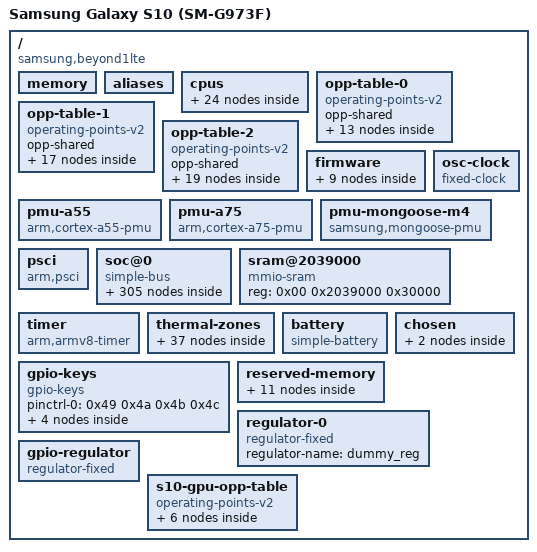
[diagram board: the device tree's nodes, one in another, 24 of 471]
// SPDX-License-Identifier: GPL-2.0-only
/* Flattened working source derived from chiffathefox/u-boot at
 * dec4927b4ad5b789b0854050096fc80250627de7.
 * Original Exynos device-tree source notices:
 * Copyright (c) 2025 chiffathefox <chiffathefoxx@gmail.com>
 * Copyright (c) 2026 chiffathefox <chiffathefoxx@gmail.com>
 * GPL version 2 is selected from the upstream GPL-2.0 OR BSD-3-Clause grant;
 * the included TMU source is GPL-2.0. Local port changes use the project GPLv2 grant.
 * Source/capture comparison and scope: docs/public/PROVENANCE.md.
 */
/dts-v1/;

/ {
	compatible = "samsung,beyond1lte", "samsung,exynos9820";
	#address-cells = <0x02>;
	#size-cells = <0x01>;
	interrupt-parent = <0x01>;
	model = "Samsung Galaxy S10 (SM-G973F)";
	chassis-type = "handset";

	memory {
		reg = <0x00 0x80000000 0x3ab00000 0x00 0xc0000000 0x20000000 0x00 0xe1900000 0x1e700000 0x08 0x80000000 0x80000000 0x09 0x00 0x80000000 0x09 0x80000000 0x80000000>;
		device_type = "memory";
	};

	aliases {
		pinctrl0 = "/soc@0/pinctrl@15850000";
		pinctrl1 = "/soc@0/pinctrl@18c60000";
		pinctrl2 = "/soc@0/pinctrl@15c30000";
		pinctrl3 = "/soc@0/pinctrl@13030000";
		pinctrl4 = "/soc@0/pinctrl@13c40000";
		pinctrl5 = "/soc@0/pinctrl@10430000";
		pinctrl6 = "/soc@0/pinctrl@10830000";
		pinctrl7 = "/soc@0/pinctrl@15580000";
		serial1 = "/soc@0/serial@10840000";
	};

	cpus {
		#address-cells = <0x01>;
		#size-cells = <0x00>;

		cpu-map {

			cluster0 {

				core0 {
					cpu = <0x02>;
				};

				core1 {
					cpu = <0x03>;
				};

				core2 {
					cpu = <0x04>;
				};

				core3 {
					cpu = <0x05>;
				};
			};

			cluster1 {

				core0 {
					cpu = <0x06>;
				};

				core1 {
					cpu = <0x07>;
				};
			};

			cluster2 {

				core0 {
					cpu = <0x08>;
				};

				core1 {
					cpu = <0x09>;
				};
			};
		};

		cpu@0 {
			device_type = "cpu";
			compatible = "arm,cortex-a55";
			reg = <0x00>;
			clocks = <0x0a 0x02>;
			#cooling-cells = <0x02>;
			enable-method = "psci";
			cpu-idle-states = <0x0b>;
			capacity-dmips-mhz = <0x110>;
			dynamic-power-coefficient = <0xa0>;
			operating-points-v2 = <0x0c>;
			phandle = <0x02>;
		};

		cpu@1 {
			device_type = "cpu";
			compatible = "arm,cortex-a55";
			reg = <0x01>;
			clocks = <0x0a 0x02>;
			#cooling-cells = <0x02>;
			enable-method = "psci";
			cpu-idle-states = <0x0b>;
			capacity-dmips-mhz = <0x110>;
			dynamic-power-coefficient = <0xa0>;
			operating-points-v2 = <0x0c>;
			phandle = <0x03>;
		};

		cpu@2 {
			device_type = "cpu";
			compatible = "arm,cortex-a55";
			reg = <0x02>;
			clocks = <0x0a 0x02>;
			#cooling-cells = <0x02>;
			enable-method = "psci";
			cpu-idle-states = <0x0b>;
			capacity-dmips-mhz = <0x110>;
			dynamic-power-coefficient = <0xa0>;
			operating-points-v2 = <0x0c>;
			phandle = <0x04>;
		};

		cpu@3 {
			device_type = "cpu";
			compatible = "arm,cortex-a55";
			reg = <0x03>;
			clocks = <0x0a 0x02>;
			#cooling-cells = <0x02>;
			enable-method = "psci";
			cpu-idle-states = <0x0b>;
			capacity-dmips-mhz = <0x110>;
			dynamic-power-coefficient = <0xa0>;
			operating-points-v2 = <0x0c>;
			phandle = <0x05>;
		};

		cpu@4 {
			device_type = "cpu";
			compatible = "arm,cortex-a75";
			reg = <0x04>;
			clocks = <0x0a 0x03>;
			#cooling-cells = <0x02>;
			enable-method = "psci";
			cpu-idle-states = <0x0d>;
			capacity-dmips-mhz = <0x213>;
			dynamic-power-coefficient = <0x140>;
			operating-points-v2 = <0x0e>;
			phandle = <0x06>;
		};

		cpu@5 {
			device_type = "cpu";
			compatible = "arm,cortex-a75";
			reg = <0x05>;
			clocks = <0x0a 0x03>;
			#cooling-cells = <0x02>;
			enable-method = "psci";
			cpu-idle-states = <0x0d>;
			capacity-dmips-mhz = <0x213>;
			dynamic-power-coefficient = <0x140>;
			operating-points-v2 = <0x0e>;
			phandle = <0x07>;
		};

		cpu@100 {
			device_type = "cpu";
			compatible = "samsung,mongoose-m4";
			reg = <0x100>;
			clocks = <0x0a 0x04>;
			#cooling-cells = <0x02>;
			enable-method = "psci";
			cpu-idle-states = <0x0f>;
			capacity-dmips-mhz = <0x311>;
			dynamic-power-coefficient = <0x2f8>;
			operating-points-v2 = <0x10>;
			phandle = <0x08>;
		};

		cpu@101 {
			device_type = "cpu";
			compatible = "samsung,mongoose-m4";
			reg = <0x101>;
			clocks = <0x0a 0x04>;
			#cooling-cells = <0x02>;
			enable-method = "psci";
			cpu-idle-states = <0x0f>;
			capacity-dmips-mhz = <0x311>;
			dynamic-power-coefficient = <0x2f8>;
			operating-points-v2 = <0x10>;
			phandle = <0x09>;
		};

		idle-states {
			entry-method = "psci";

			cpu-ananke-sleep {
				samsung,cpuidle-disabled-by-default = "deferred-until-userspace-v1";
				idle-state-name = "c2";
				compatible = "arm,idle-state";
				arm,psci-suspend-param = <0x10000>;
				entry-latency-us = <0x46>;
				exit-latency-us = <0xa0>;
				min-residency-us = <0x7d0>;
				status = "okay";
				phandle = <0x0b>;
			};

			cpu-prometheus-sleep {
				samsung,cpuidle-disabled-by-default = "deferred-until-userspace-v1";
				idle-state-name = "c2";
				compatible = "arm,idle-state";
				arm,psci-suspend-param = <0x10000>;
				entry-latency-us = <0x96>;
				exit-latency-us = <0xbe>;
				min-residency-us = <0x9c4>;
				status = "okay";
				phandle = <0x0d>;
			};

			cpu-cheetah-sleep {
				samsung,cpuidle-disabled-by-default = "deferred-until-userspace-v1";
				idle-state-name = "c2";
				compatible = "arm,idle-state";
				arm,psci-suspend-param = <0x10000>;
				entry-latency-us = <0xeb>;
				exit-latency-us = <0xdc>;
				min-residency-us = <0xdac>;
				status = "okay";
				phandle = <0x0f>;
			};
		};
	};

	opp-table-0 {
		compatible = "operating-points-v2";
		opp-shared;
		phandle = <0x0c>;

		opp-442000000 {
			opp-hz = <0x00 0x1a586280>;
			opp-microvolt = <0x8de82>;
			clock-latency-ns = <0x7a120>;
		};

		opp-546000000 {
			opp-hz = <0x00 0x208b4c80>;
			opp-microvolt = <0x95894>;
			clock-latency-ns = <0x7a120>;
		};

		opp-650000000 {
			opp-hz = <0x00 0x26be3680>;
			opp-microvolt = <0x9a1d2>;
			clock-latency-ns = <0x7a120>;
		};

		opp-806000000 {
			opp-hz = <0x00 0x300a9580>;
			opp-microvolt = <0xa4cb8>;
			clock-latency-ns = <0x7a120>;
		};

		opp-949000000 {
			opp-hz = <0x00 0x38909740>;
			opp-microvolt = <0xadf34>;
			clock-latency-ns = <0x7a120>;
		};

		opp-1053000000 {
			opp-hz = <0x00 0x3ec38140>;
			opp-microvolt = <0xb5946>;
			clock-latency-ns = <0x7a120>;
		};

		opp-1157000000 {
			opp-hz = <0x00 0x44f66b40>;
			opp-microvolt = <0xbd358>;
			clock-latency-ns = <0x7a120>;
		};

		opp-1300000000 {
			opp-hz = <0x00 0x4d7c6d00>;
			opp-microvolt = <0xc7e3e>;
			clock-latency-ns = <0x7a120>;
		};

		opp-1456000000 {
			opp-hz = <0x00 0x56c8cc00>;
			opp-microvolt = <0xd418e>;
			clock-latency-ns = <0x7a120>;
		};

		opp-1586000000 {
			opp-hz = <0x00 0x5e887080>;
			opp-microvolt = <0xe04de>;
			clock-latency-ns = <0x7a120>;
		};

		opp-1742000000 {
			opp-hz = <0x00 0x67d4cf80>;
			opp-microvolt = <0xf4240>;
			clock-latency-ns = <0x7a120>;
		};

		opp-1846000000 {
			opp-hz = <0x00 0x6e07b980>;
			opp-microvolt = <0x100590>;
			clock-latency-ns = <0x7a120>;
		};

		opp-1950000000 {
			opp-hz = <0x00 0x743aa380>;
			opp-microvolt = <0x10b076>;
			clock-latency-ns = <0x7a120>;
		};
	};

	opp-table-1 {
		compatible = "operating-points-v2";
		opp-shared;
		phandle = <0x0e>;

		opp-507000000 {
			opp-hz = <0x00 0x1e3834c0>;
			opp-microvolt = <0x8f6ec>;
			clock-latency-ns = <0x7a120>;
		};

		opp-650000000 {
			opp-hz = <0x00 0x26be3680>;
			opp-microvolt = <0x9402a>;
			clock-latency-ns = <0x7a120>;
		};

		opp-754000000 {
			opp-hz = <0x00 0x2cf12080>;
			opp-microvolt = <0x9a1d2>;
			clock-latency-ns = <0x7a120>;
		};

		opp-845000000 {
			opp-hz = <0x00 0x325dad40>;
			opp-microvolt = <0x9eb10>;
			clock-latency-ns = <0x7a120>;
		};

		opp-962000000 {
			opp-hz = <0x00 0x3956f480>;
			opp-microvolt = <0xa1be4>;
			clock-latency-ns = <0x7a120>;
		};

		opp-1066000000 {
			opp-hz = <0x00 0x3f89de80>;
			opp-microvolt = <0xa6522>;
			clock-latency-ns = <0x7a120>;
		};

		opp-1222000000 {
			opp-hz = <0x00 0x48d63d80>;
			opp-microvolt = <0xb1008>;
			clock-latency-ns = <0x7a120>;
		};

		opp-1404000000 {
			opp-hz = <0x00 0x53af5700>;
			opp-microvolt = <0xb8a1a>;
			clock-latency-ns = <0x7a120>;
		};

		opp-1508000000 {
			opp-hz = <0x00 0x59e24100>;
			opp-microvolt = <0xbebc2>;
			clock-latency-ns = <0x7a120>;
		};

		opp-1586000000 {
			opp-hz = <0x00 0x5e887080>;
			opp-microvolt = <0xc1c96>;
			clock-latency-ns = <0x7a120>;
		};

		opp-1690000000 {
			opp-hz = <0x00 0x64bb5a80>;
			opp-microvolt = <0xc7e3e>;
			clock-latency-ns = <0x7a120>;
		};

		opp-1794000000 {
			opp-hz = <0x00 0x6aee4480>;
			opp-microvolt = <0xcf850>;
			clock-latency-ns = <0x7a120>;
		};

		opp-1898000000 {
			opp-hz = <0x00 0x71212e80>;
			opp-microvolt = <0xda336>;
			clock-latency-ns = <0x7a120>;
		};

		opp-2002000000 {
			opp-hz = <0x00 0x77541880>;
			opp-microvolt = <0xe04de>;
			clock-latency-ns = <0x7a120>;
		};

		opp-2106000000 {
			opp-hz = <0x00 0x7d870280>;
			opp-microvolt = <0xe975a>;
			clock-latency-ns = <0x7a120>;
		};

		opp-2210000000 {
			opp-hz = <0x00 0x83b9ec80>;
			opp-microvolt = <0xf5aaa>;
			clock-latency-ns = <0x7a120>;
		};

		opp-2314000000 {
			opp-hz = <0x00 0x89ecd680>;
			opp-microvolt = <0x101dfa>;
			clock-latency-ns = <0x7a120>;
		};
	};

	opp-table-2 {
		compatible = "operating-points-v2";
		opp-shared;
		phandle = <0x10>;

		opp-520000000 {
			opp-hz = <0x00 0x1efe9200>;
			opp-microvolt = <0x8f6ec>;
			clock-latency-ns = <0x7a120>;
		};

		opp-624000000 {
			opp-hz = <0x00 0x25317c00>;
			opp-microvolt = <0x927c0>;
			clock-latency-ns = <0x7a120>;
		};

		opp-728000000 {
			opp-hz = <0x00 0x2b646600>;
			opp-microvolt = <0x9402a>;
			clock-latency-ns = <0x7a120>;
		};

		opp-819000000 {
			opp-hz = <0x00 0x30d0f2c0>;
			opp-microvolt = <0x970fe>;
			clock-latency-ns = <0x7a120>;
		};

		opp-936000000 {
			opp-hz = <0x00 0x37ca3a00>;
			opp-microvolt = <0x9ba3c>;
			clock-latency-ns = <0x7a120>;
		};

		opp-1040000000 {
			opp-hz = <0x00 0x3dfd2400>;
			opp-microvolt = <0x9d2a6>;
			clock-latency-ns = <0x7a120>;
		};

		opp-1144000000 {
			opp-hz = <0x00 0x44300e00>;
			opp-microvolt = <0xa4cb8>;
			clock-latency-ns = <0x7a120>;
		};

		opp-1248000000 {
			opp-hz = <0x00 0x4a62f800>;
			opp-microvolt = <0xa7d8c>;
			clock-latency-ns = <0x7a120>;
		};

		opp-1378000000 {
			opp-hz = <0x00 0x52229c80>;
			opp-microvolt = <0xac6ca>;
			clock-latency-ns = <0x7a120>;
		};

		opp-1456000000 {
			opp-hz = <0x00 0x56c8cc00>;
			opp-microvolt = <0xaf79e>;
			clock-latency-ns = <0x7a120>;
		};

		opp-1560000000 {
			opp-hz = <0x00 0x5cfbb600>;
			opp-microvolt = <0xb5946>;
			clock-latency-ns = <0x7a120>;
		};

		opp-1664000000 {
			opp-hz = <0x00 0x632ea000>;
			opp-microvolt = <0xbbaee>;
			clock-latency-ns = <0x7a120>;
		};

		opp-1820000000 {
			opp-hz = <0x00 0x6c7aff00>;
			opp-microvolt = <0xc1c96>;
			clock-latency-ns = <0x7a120>;
		};

		opp-1976000000 {
			opp-hz = <0x00 0x75c75e00>;
			opp-microvolt = <0xcc77c>;
			clock-latency-ns = <0x7a120>;
		};

		opp-2080000000 {
			opp-hz = <0x00 0x7bfa4800>;
			opp-microvolt = <0xd418e>;
			clock-latency-ns = <0x7a120>;
		};

		opp-2236000000 {
			opp-hz = <0x00 0x8546a700>;
			opp-microvolt = <0xdd40a>;
			clock-latency-ns = <0x7a120>;
		};

		opp-2340000000 {
			opp-hz = <0x00 0x8b799100>;
			opp-microvolt = <0xe35b2>;
			clock-latency-ns = <0x7a120>;
		};

		opp-2470000000 {
			opp-hz = <0x00 0x93393580>;
			opp-microvolt = <0xf116c>;
			clock-latency-ns = <0x7a120>;
		};

		opp-2530000000 {
			opp-hz = <0x00 0x96ccbc80>;
			opp-microvolt = <0xf8b7e>;
			clock-latency-ns = <0x7a120>;
		};
	};

	firmware {

		power-management {
			compatible = "samsung,exynos9820-acpm-ipc";
			#clock-cells = <0x01>;
			assigned-clocks = <0x0a 0x00 0x0a 0x01 0x0a 0x02 0x0a 0x03 0x0a 0x04 0x0a 0x05 0x0a 0x06 0x0a 0x07 0x0a 0x08 0x0a 0x09 0x0a 0x0a 0x0a 0x0b 0x0a 0x0c 0x0a 0x0d 0x0a 0x0e>;
			assigned-clock-rates = <0x7cc0a540 0x1fd43180 0x3ec38140 0x48d63d80 0x52229c80 0x9f437c0 0x1fd43180 0x17d7840 0x119557c0 0x3f89de80 0x94c5f00 0x258d0980 0x26be3680 0x3567e00 0x7fcad80>;
			mboxes = <0x11>;
			shmem = <0x12>;
			phandle = <0x0a>;

			pmic-1 {
				compatible = "samsung,s2mps19-pmic";
				interrupts-extended = <0x13 0x01 0x08>;
				wakeup-source;

				regulators {

					ldo19m {
						regulator-name = "tsp_io";
						regulator-min-microvolt = <0x1b7740>;
						regulator-max-microvolt = <0x1b7740>;
						regulator-boot-on;
						phandle = <0x1c>;
					};

					ldo27m {
						regulator-name = "tsp_avdd";
						regulator-min-microvolt = <0x2dc6c0>;
						regulator-max-microvolt = <0x2dc6c0>;
						regulator-boot-on;
						phandle = <0x1b>;
					};

					ldo17m {
						regulator-name = "vdd_pmic_codec_1p8";
						regulator-min-microvolt = <0x1b7740>;
						regulator-max-microvolt = <0x1b7740>;
						regulator-always-on;
						regulator-boot-on;
						phandle = <0x58>;
					};

					ldo18m {
						regulator-name = "vdd_codec_1p2";
						regulator-min-microvolt = <0x124f80>;
						regulator-max-microvolt = <0x124f80>;
						phandle = <0x59>;
					};

					ldo22m {
						regulator-name = "VDD_NFC_1P8";
						regulator-min-microvolt = <0x1b7740>;
						regulator-max-microvolt = <0x1b7740>;
						regulator-boot-on;
						regulator-always-on;
					};

					ldo21m {
						regulator-name = "vdd_mcu_1p8";
						regulator-min-microvolt = <0x1b7740>;
						regulator-max-microvolt = <0x1b7740>;
						regulator-boot-on;
						regulator-always-on;
					};
				};
			};
		};
	};

	osc-clock {
		compatible = "fixed-clock";
		#clock-cells = <0x00>;
		clock-output-names = "oscclk";
		clock-frequency = <0x18cba80>;
		phandle = <0x14>;
	};

	pmu-a55 {
		compatible = "arm,cortex-a55-pmu";
		interrupts = <0x00 0x8d 0x04 0x00 0x8e 0x04 0x00 0x8f 0x04 0x00 0x90 0x04>;
		interrupt-affinity = <0x02 0x03 0x04 0x05>;
	};

	pmu-a75 {
		compatible = "arm,cortex-a75-pmu";
		interrupts = <0x00 0x91 0x04 0x00 0x92 0x04>;
		interrupt-affinity = <0x06 0x07>;
	};

	pmu-mongoose-m4 {
		compatible = "samsung,mongoose-pmu";
		interrupts = <0x00 0xae 0x04 0x00 0xaf 0x04>;
		interrupt-affinity = <0x08 0x09>;
	};

	psci {
		compatible = "arm,psci";
		method = "smc";
		cpu_suspend = <0xc4000001>;
		cpu_off = <0x84000002>;
		cpu_on = <0xc4000003>;
	};

	soc@0 {
		compatible = "simple-bus";
		#address-cells = <0x01>;
		#size-cells = <0x01>;
		ranges = <0x00 0x00 0x00 0x20000000>;

		watchdog@10050000 {
			status = "okay";
			timeout-sec = <0x14>;
			samsung,syscon-phandle = <0x21>;
			clock-names = "watchdog", "watchdog_src";
			clocks = <0x17 0x16 0x14>;
			interrupts = <0x00 0x1d0 0x04>;
			reg = <0x10050000 0x100>;
			compatible = "samsung,exynos9820-wdt";
		};

		sysmmu@190a0000 {
			phandle = <0xaa>;
			#iommu-cells = <0x00>;
			clocks = <0x39 0x3c>;
			clock-names = "sysmmu";
			interrupts = <0x00 0xd4 0x04>;
			reg = <0x190a0000 0x9000>;
			compatible = "samsung,exynos-sysmmu";
		};

		display-controller@19030000 {
			interrupt-names = "frame-done", "frame-start";
			phandle = <0xab>;
			iommus = <0xaa>;
			height-mm = <0x8c>;
			width-mm = <0x42>;
			interrupts = <0x00 0xb8 0x04 0x00 0xb7 0x04>;
			memory-region = <0xa9>;
			reg-names = "decon", "dma", "dsim";
			reg = <0x19030000 0x10000 0x19071000 0x1000 0x19080000 0x300>;
			compatible = "samsung,exynos9820-decon-takeover";
		};

		flexpmu-dbg@204bc00 {
			compatible = "samsung,exynos9820-flexpmu-dbg";
			reg = <0x204bc00 0x400 0x15950000 0x100>;
			reg-names = "data", "rtc";
		};

		clock-controller@10020000 {
			compatible = "samsung,exynos9820-cmu-peris";
			reg = <0x10020000 0x10000>;
			#clock-cells = <0x01>;
			clock-names = "oscclk", "bus";
			clocks = <0x14 0x15 0x6b>;
			samsung,sysreg = <0x16>;
			phandle = <0x17>;
		};

		syscon@10030000 {
			compatible = "samsung,exynos9820-peris-sysreg", "syscon";
			reg = <0x10030000 0x10000>;
			clocks = <0x17 0x13>;
			phandle = <0x16>;
		};

		timer@10040000 {
			samsung,prefer-local-timers;
			compatible = "samsung,exynos4210-mct";
			reg = <0x10040000 0x800>;
			clocks = <0x14 0x17 0x0d>;
			clock-names = "fin_pll", "mct";
			interrupts = <0x00 0x1d2 0x04 0x00 0x1d3 0x04 0x00 0x1d4 0x04 0x00 0x1d5 0x04 0x00 0x1d6 0x04 0x00 0x1d7 0x04 0x00 0x1d8 0x04 0x00 0x1d9 0x04 0x00 0x1da 0x04 0x00 0x1db 0x04 0x00 0x1dc 0x04 0x00 0x1dd 0x04>;
		};

		thermal-sensor@10090000 {
			compatible = "samsung,exynos9820-tmu-top";
			reg = <0x10090000 0x800>;
			clocks = <0x17 0x15 0x17 0x14>;
			interrupts = <0x00 0x1de 0x04>;
			samsung,acpm-ipc = <0x0a>;
			#thermal-sensor-cells = <0x01>;
			phandle = <0x43>;
		};

		interrupt-controller@10100000 {
			compatible = "arm,cortex-a15-gic", "arm,cortex-a9-gic";
			#interrupt-cells = <0x03>;
			#address-cells = <0x00>;
			interrupt-controller;
			reg = <0x10101000 0x1000 0x10102000 0x1000 0x10104000 0x2000 0x10106000 0x2000>;
			interrupts = <0x01 0x09 0xf04>;
			phandle = <0x01>;
		};

		clock-controller@10400000 {
			compatible = "samsung,exynos9820-cmu-peric0";
			reg = <0x10400000 0x10000>;
			#clock-cells = <0x01>;
			clock-names = "oscclk", "bus", "ip";
			clocks = <0x14 0x15 0x67 0x15 0x68>;
			samsung,sysreg = <0x18>;
			phandle = <0x19>;
		};

		syscon@10420000 {
			compatible = "samsung,exynos9820-peric0-sysreg", "syscon";
			reg = <0x10420000 0x10000>;
			clocks = <0x19 0x2f>;
			phandle = <0x18>;
		};

		pinctrl@10430000 {
			compatible = "samsung,exynos9820-pinctrl";
			reg = <0x10430000 0x1000>;
			clocks = <0x19 0x1f>;
			clock-names = "pclk";
			interrupts = <0x00 0x17c 0x04>;

			gpp0-gpio-bank {
				gpio-controller;
				#gpio-cells = <0x02>;
				interrupt-controller;
				#interrupt-cells = <0x02>;
				phandle = <0x53>;
			};

			gpp1-gpio-bank {
				gpio-controller;
				#gpio-cells = <0x02>;
				interrupt-controller;
				#interrupt-cells = <0x02>;
			};

			gpp2-gpio-bank {
				gpio-controller;
				#gpio-cells = <0x02>;
				interrupt-controller;
				#interrupt-cells = <0x02>;
			};

			gpp3-gpio-bank {
				gpio-controller;
				#gpio-cells = <0x02>;
				interrupt-controller;
				#interrupt-cells = <0x02>;
			};

			gpg0-gpio-bank {
				gpio-controller;
				#gpio-cells = <0x02>;
				interrupt-controller;
				#interrupt-cells = <0x02>;
				phandle = <0x51>;
			};

			gpg1-gpio-bank {
				gpio-controller;
				#gpio-cells = <0x02>;
				interrupt-controller;
				#interrupt-cells = <0x02>;
				phandle = <0x4e>;
			};

			gpg2-gpio-bank {
				gpio-controller;
				#gpio-cells = <0x02>;
				interrupt-controller;
				#interrupt-cells = <0x02>;
				phandle = <0x86>;
			};

			gpg4-gpio-bank {
				gpio-controller;
				#gpio-cells = <0x02>;
				interrupt-controller;
				#interrupt-cells = <0x02>;
				phandle = <0x75>;
			};

			hsi2c10-bus-pins {
				samsung,pins = "gpp1-4", "gpp1-5";
				samsung,pin-function = <0x02>;
				samsung,pin-pud = <0x00>;
				samsung,pin-drv = <0x00>;
				phandle = <0x1a>;
			};

			s10-spi2-bus {
				samsung,pins = "gpp0-4", "gpp0-5", "gpp0-6";
				samsung,pin-function = <0x02>;
				samsung,pin-pud = <0x00>;
				phandle = <0x54>;
			};

			s10-spi2-cs {
				samsung,pins = "gpp0-7";
				samsung,pin-function = <0x01>;
				samsung,pin-pud = <0x03>;
				phandle = <0x55>;
			};

			s10-codec-reset {
				samsung,pins = "gpg1-0";
				samsung,pin-function = <0x01>;
				samsung,pin-pud = <0x00>;
				phandle = <0x56>;
			};

			s10-bt-btwake {
				samsung,pins = "gpg2-0";
				samsung,pin-function = <0x01>;
				samsung,pin-pud = <0x00>;
				phandle = <0x99>;
			};

			s10-shub-pwr {
				samsung,pins = "gpg0-2";
				samsung,pin-function = <0x01>;
				samsung,pin-pud = <0x01>;
				samsung,pin-drv = <0x03>;
				phandle = <0xa3>;
			};

			s10-shub-mcu-req {
				samsung,pins = "gpg4-1";
				samsung,pin-function = <0x01>;
				samsung,pin-pud = <0x00>;
				samsung,pin-drv = <0x03>;
				phandle = <0xa4>;
			};

			s10-shub-mcu-resp {
				samsung,pins = "gpg4-2";
				samsung,pin-function = <0x00>;
				samsung,pin-pud = <0x00>;
				samsung,pin-drv = <0x03>;
				phandle = <0xa5>;
			};
		};

		serial@10440000 {
			compatible = "samsung,exynos7870-uart", "samsung,exynos8895-uart";
			reg = <0x10440000 0x100>;
			interrupts = <0x00 0x17d 0x04>;
			clock-names = "uart", "clk_uart_baud0";
			clocks = <0x19 0x31 0x19 0x30>;
			samsung,uart-fifosize = <0x100>;
			status = "okay";
		};

		usi@104b00c0 {
			compatible = "samsung,exynos850-usi";
			reg = <0x104b00c0 0x20>;
			ranges;
			clock-names = "pclk", "ipclk";
			clocks = <0x19 0x41 0x19 0x40>;
			#address-cells = <0x01>;
			#size-cells = <0x01>;
			samsung,sysreg = <0x18 0x101c>;
			status = "okay";
			samsung,mode = <0x03>;

			i2c@104b0000 {
				compatible = "samsung,exynosautov9-hsi2c";
				reg = <0x104b0000 0xc0>;
				clock-names = "hsi2c", "hsi2c_pclk";
				clocks = <0x19 0x40 0x19 0x41>;
				interrupts = <0x00 0x184 0x04>;
				pinctrl-0 = <0x1a>;
				pinctrl-names = "default";
				#address-cells = <0x01>;
				#size-cells = <0x00>;
				status = "okay";
				clock-frequency = <0x61a80>;

				touchscreen@48 {
					compatible = "samsung,s6sy761";
					reg = <0x48>;
					avdd-supply = <0x1b>;
					vdd-supply = <0x1c>;
					interrupts-extended = <0x1d 0x00 0x08>;
					pinctrl-0 = <0x1e>;
					pinctrl-names = "default";
				};
			};
		};

		pwm@10510000 {
			compatible = "samsung,exynos4210-pwm";
			reg = <0x10510000 0x1000>;
			samsung,pwm-outputs = <0x00 0x01 0x02 0x03 0x04>;
			#pwm-cells = <0x03>;
			clocks = <0x14>;
			clock-names = "timers";
			status = "okay";
			phandle = <0x35>;
		};

		clock-controller@10800000 {
			compatible = "samsung,exynos9820-cmu-peric1";
			reg = <0x10800000 0x10000>;
			#clock-cells = <0x01>;
			clock-names = "oscclk", "bus";
			clocks = <0x14 0x15 0x69>;
			samsung,sysreg = <0x1f>;
			phandle = <0x5a>;
		};

		syscon@10820000 {
			compatible = "samsung,exynos9820-peric1-sysreg", "syscon";
			reg = <0x10820000 0x10000>;
			phandle = <0x1f>;
		};

		pinctrl@10830000 {
			compatible = "samsung,exynos9820-pinctrl";
			reg = <0x10830000 0x1000>;
			interrupts = <0x00 0x197 0x04>;

			gpp4-gpio-bank {
				gpio-controller;
				#gpio-cells = <0x02>;
				interrupt-controller;
				#interrupt-cells = <0x02>;
			};

			gpp5-gpio-bank {
				gpio-controller;
				#gpio-cells = <0x02>;
				interrupt-controller;
				#interrupt-cells = <0x02>;
			};

			gpp6-gpio-bank {
				gpio-controller;
				#gpio-cells = <0x02>;
				interrupt-controller;
				#interrupt-cells = <0x02>;
				phandle = <0x9c>;
			};

			gpc0-gpio-bank {
				gpio-controller;
				#gpio-cells = <0x02>;
				interrupt-controller;
				#interrupt-cells = <0x02>;
			};

			gpc1-gpio-bank {
				gpio-controller;
				#gpio-cells = <0x02>;
				interrupt-controller;
				#interrupt-cells = <0x02>;
			};

			gpd0-gpio-bank {
				gpio-controller;
				#gpio-cells = <0x02>;
				interrupt-controller;
				#interrupt-cells = <0x02>;
			};

			gpg3-gpio-bank {
				gpio-controller;
				#gpio-cells = <0x02>;
				interrupt-controller;
				#interrupt-cells = <0x02>;
				phandle = <0x7a>;
			};

			gph0-gpio-bank {
				gpio-controller;
				#gpio-cells = <0x02>;
				interrupt-controller;
				#interrupt-cells = <0x02>;
				phandle = <0xa2>;
			};

			gph1-gpio-bank {
				gpio-controller;
				#gpio-cells = <0x02>;
				interrupt-controller;
				#interrupt-cells = <0x02>;
				phandle = <0x5f>;
			};

			s10-amp-i2c-bus {
				samsung,pins = "gph0-6", "gph0-7";
				samsung,pin-function = <0x03>;
				samsung,pin-pud = <0x00>;
				phandle = <0x5b>;
			};

			s10-amp-reset-released {
				samsung,pins = "gph1-1", "gph1-2";
				samsung,pin-function = <0x01>;
				samsung,pin-pud = <0x00>;
				samsung,pin-val = <0x01>;
			};

			s10-amp-reset {
				samsung,pins = "gph1-1", "gph1-2";
				samsung,pin-function = <0x01>;
				samsung,pin-pud = <0x00>;
				phandle = <0x5c>;
			};

			s10-camera-pmic-bus {
				samsung,pins = "gpp6-0", "gpp6-1";
				samsung,pin-function = <0x02>;
				samsung,pin-pud = <0x00>;
				samsung,pin-drv = <0x00>;
				phandle = <0x66>;
			};

			s10-uw-i2c-idle {
				samsung,pins = "gpc0-2", "gpc0-3";
				samsung,pin-function = <0x00>;
				samsung,pin-pud = <0x00>;
				phandle = <0x67>;
			};

			s10-uw-i2c-active {
				samsung,pins = "gpc0-2", "gpc0-3";
				samsung,pin-function = <0x02>;
				samsung,pin-pud = <0x00>;
				samsung,pin-drv = <0x00>;
				phandle = <0x69>;
			};

			s10-uw-mclk-idle {
				samsung,pins = "gpc1-7";
				samsung,pin-function = <0x01>;
				samsung,pin-val = <0x00>;
				samsung,pin-pud = <0x01>;
				phandle = <0x68>;
			};

			s10-uw-mclk-active {
				samsung,pins = "gpc1-7";
				samsung,pin-function = <0x02>;
				samsung,pin-pud = <0x00>;
				samsung,pin-drv = <0x00>;
				phandle = <0x6a>;
			};

			s10-tele-i2c-idle {
				samsung,pins = "gpp4-6", "gpp4-7";
				samsung,pin-function = <0x00>;
				samsung,pin-pud = <0x00>;
				phandle = <0x76>;
			};

			s10-tele-i2c-active {
				samsung,pins = "gpp4-6", "gpp4-7";
				samsung,pin-function = <0x03>;
				samsung,pin-pud = <0x00>;
				samsung,pin-drv = <0x00>;
				phandle = <0x78>;
			};

			s10-front-i2c-idle {
				samsung,pins = "gpc0-4", "gpc0-5";
				samsung,pin-function = <0x00>;
				samsung,pin-pud = <0x00>;
				phandle = <0x82>;
			};

			s10-front-i2c-active {
				samsung,pins = "gpc0-4", "gpc0-5";
				samsung,pin-function = <0x02>;
				samsung,pin-pud = <0x00>;
				samsung,pin-drv = <0x00>;
				phandle = <0x84>;
			};

			s10-af-i2c-idle {
				samsung,pins = "gpc0-6", "gpc0-7";
				samsung,pin-function = <0x00>;
				samsung,pin-pud = <0x00>;
				phandle = <0x8b>;
			};

			s10-af-i2c-active {
				samsung,pins = "gpc0-6", "gpc0-7";
				samsung,pin-function = <0x02>;
				samsung,pin-pud = <0x02>;
				samsung,pin-drv = <0x00>;
				phandle = <0x8c>;
			};

			s10-mclk0-idle {
				samsung,pins = "gpc1-4";
				samsung,pin-function = <0x01>;
				samsung,pin-val = <0x00>;
				samsung,pin-pud = <0x01>;
				phandle = <0x77>;
			};

			s10-mclk0-active {
				samsung,pins = "gpc1-4";
				samsung,pin-function = <0x02>;
				samsung,pin-pud = <0x00>;
				samsung,pin-drv = <0x00>;
				phandle = <0x79>;
			};

			s10-mclk1-idle {
				samsung,pins = "gpc1-5";
				samsung,pin-function = <0x01>;
				samsung,pin-val = <0x00>;
				samsung,pin-pud = <0x01>;
				phandle = <0x83>;
			};

			s10-mclk1-active {
				samsung,pins = "gpc1-5";
				samsung,pin-function = <0x02>;
				samsung,pin-pud = <0x00>;
				samsung,pin-drv = <0x00>;
				phandle = <0x85>;
			};

			s10-front-af-i2c-idle {
				samsung,pins = "gpp5-2", "gpp5-3";
				samsung,pin-function = <0x00>;
				samsung,pin-pud = <0x00>;
				phandle = <0x93>;
			};

			s10-front-af-i2c-active {
				samsung,pins = "gpp5-2", "gpp5-3";
				samsung,pin-function = <0x03>;
				samsung,pin-pud = <0x00>;
				samsung,pin-drv = <0x00>;
				phandle = <0x94>;
			};

			s10-nfc-i2c {
				samsung,pins = "gpp5-0", "gpp5-1";
				samsung,pin-function = <0x02>;
				samsung,pin-pud = <0x00>;
				samsung,pin-drv = <0x00>;
				phandle = <0x9b>;
			};

			s10-nfc-en {
				samsung,pins = "gpp6-2";
				samsung,pin-function = <0x01>;
				samsung,pin-pud = <0x00>;
				phandle = <0x9d>;
			};

			s10-nfc-firm {
				samsung,pins = "gpp6-3";
				samsung,pin-function = <0x01>;
				samsung,pin-pud = <0x00>;
				phandle = <0x9e>;
			};

			s10-shub-spi {
				samsung,pins = "gph0-2", "gph0-1", "gph0-0";
				samsung,pin-function = <0x02>;
				samsung,pin-pud = <0x00>;
				samsung,pin-drv = <0x00>;
				phandle = <0xa0>;
			};

			s10-shub-cs {
				samsung,pins = "gph0-3";
				samsung,pin-function = <0x01>;
				samsung,pin-pud = <0x00>;
				samsung,pin-drv = <0x00>;
				phandle = <0xa1>;
			};

			s10-main-i2c-idle {
				samsung,pins = "gpc0-0", "gpc0-1";
				samsung,pin-function = <0x00>;
				samsung,pin-pud = <0x00>;
				phandle = <0xac>;
			};

			s10-main-i2c-active {
				samsung,pins = "gpc0-0", "gpc0-1";
				samsung,pin-function = <0x02>;
				samsung,pin-pud = <0x00>;
				samsung,pin-drv = <0x00>;
				phandle = <0xad>;
			};
		};

		clock-controller@10a00000 {
			compatible = "samsung,exynos9820-cmu-fsys0a";
			reg = <0x10a00000 0x10000>;
			#clock-cells = <0x01>;
			clock-names = "oscclk", "usb31drd", "usbdp_debug";
			clocks = <0x14 0x15 0x53 0x15 0x7a>;
			phandle = <0x20>;
		};

		phy@10b00000 {
			compatible = "samsung,exynos990-usbdrd-phy";
			reg = <0x10b00000 0x200>;
			#phy-cells = <0x01>;
			clock-names = "phy", "ref";
			clocks = <0x20 0x0a 0x14>;
			samsung,pmu-syscon = <0x21>;
			status = "okay";
			phandle = <0x23>;
		};

		usb@10c00000 {
			compatible = "samsung,exynos850-dwusb3";
			ranges = <0x00 0x10c00000 0x10000>;
			clock-names = "bus_early", "ref";
			clocks = <0x20 0x0b 0x20 0x0c>;
			#address-cells = <0x01>;
			#size-cells = <0x01>;
			status = "okay";
			vdd10-supply = <0x22>;
			vdd33-supply = <0x22>;

			usb@0 {
				compatible = "snps,dwc3";
				reg = <0x00 0x10000>;
				interrupts = <0x00 0xf1 0x04>;
				phys = <0x23 0x00>;
				phy-names = "usb2-phy";
			};
		};

		clock-controller@13000000 {
			compatible = "samsung,exynos9820-cmu-fsys0";
			reg = <0x13000000 0x10000>;
			#clock-cells = <0x01>;
			clock-names = "oscclk", "bus";
			clocks = <0x14 0x15 0x55>;
			samsung,sysreg = <0x24>;
		};

		syscon@13020000 {
			compatible = "samsung,exynos9820-fsys0-sysreg", "syscon";
			reg = <0x13020000 0x10000>;
			phandle = <0x24>;
		};

		pinctrl@13030000 {
			compatible = "samsung,exynos9820-pinctrl";
			reg = <0x13030000 0x1000>;
			interrupts = <0x00 0xf0 0x04>;

			gpf0-gpio-bank {
				gpio-controller;
				#gpio-cells = <0x02>;
				interrupt-controller;
				#interrupt-cells = <0x02>;
			};
		};

		clock-controller@13c00000 {
			compatible = "samsung,exynos9820-cmu-fsys1";
			reg = <0x13c00000 0x10000>;
			#clock-cells = <0x01>;
			clock-names = "oscclk", "bus", "mmc_card", "pcie", "ufs_card", "ufs_embd";
			clocks = <0x14 0x15 0x7e 0x15 0x7f 0x15 0x9c 0x15 0x9d 0x15 0x9e>;
			samsung,sysreg = <0x25>;
			phandle = <0x26>;
		};

		syscon@13c10000 {
			compatible = "samsung,exynos9820-fsys1-sysreg", "syscon";
			reg = <0x13c10000 0x1200>;
			clocks = <0x26 0x2c>;
			phandle = <0x25>;
		};

		pinctrl@13c40000 {
			compatible = "samsung,exynos9820-pinctrl";
			reg = <0x13c40000 0x1000>;
			clocks = <0x26 0x12>;
			clock-names = "pclk";
			interrupts = <0x00 0xfb 0x04>;

			gpf1-gpio-bank {
				gpio-controller;
				#gpio-cells = <0x02>;
				interrupt-controller;
				#interrupt-cells = <0x02>;
			};

			gpf2-gpio-bank {
				gpio-controller;
				#gpio-cells = <0x02>;
				interrupt-controller;
				#interrupt-cells = <0x02>;
				phandle = <0x50>;
			};

			gpf3-gpio-bank {
				gpio-controller;
				#gpio-cells = <0x02>;
				interrupt-controller;
				#interrupt-cells = <0x02>;
			};

			s10-pcie0-clkreq {
				samsung,pins = "gpf2-0";
				samsung,pin-function = <0x02>;
				samsung,pin-pud = <0x03>;
				samsung,pin-drv = <0x03>;
				phandle = <0x52>;
			};
		};

		ufs@13d60000 {
			compatible = "samsung,exynos9820-ufs";
			reg = <0x13d60000 0x200 0x13d61100 0x200 0x13d50000 0x8000 0x13d70000 0x100>;
			reg-names = "hci", "vs_hci", "unipro", "ufsp";
			interrupts = <0x00 0xf9 0x04>;
			clock-names = "core_clk", "sclk_unipro_main", "fmp";
			clocks = <0x26 0x30 0x26 0x31 0x26 0x32>;
			freq-table-hz = <0x00 0x00 0x00 0x00 0x00 0x00>;
			phys = <0x27>;
			phy-names = "ufs-phy";
			dma-coherent;
			samsung,sysreg = <0x25 0x700>;
			status = "okay";
		};

		ufs-phy@13d64000 {
			compatible = "samsung,exynos9820-ufs-phy";
			reg = <0x13d64000 0x800>;
			reg-names = "phy-pma";
			#phy-cells = <0x00>;
			samsung,pmu-syscon = <0x21>;
			phandle = <0x27>;
		};

		pinctrl@15580000 {
			status = "disabled";
			compatible = "samsung,exynos9820-pinctrl";
			reg = <0x15580000 0x1000>;

			gpv0-gpio-bank {
				gpio-controller;
				#gpio-cells = <0x02>;
				interrupt-controller;
				#interrupt-cells = <0x02>;
			};
		};

		clock-controller@15800000 {
			compatible = "samsung,exynos9820-cmu-apm";
			reg = <0x15800000 0x10000>;
			#clock-cells = <0x01>;
			clock-names = "oscclk", "bus";
			clocks = <0x14 0x15 0x42>;
			samsung,sysreg = <0x28>;
			phandle = <0x29>;
		};

		syscon@15820000 {
			compatible = "samsung,exynos9820-apm-sysreg", "syscon";
			reg = <0x15820000 0x10000>;
			clocks = <0x29 0x2b>;
			phandle = <0x28>;
		};

		pinctrl@15850000 {
			compatible = "samsung,exynos9820-pinctrl";
			reg = <0x15850000 0x1000>;

			wakeup-interrupt-controller {
				compatible = "samsung,exynos7-wakeup-eint";
			};

			gpa0-gpio-bank {
				gpio-controller;
				#gpio-cells = <0x02>;
				interrupt-controller;
				#interrupt-cells = <0x02>;
				interrupt-parent = <0x01>;
				interrupts = <0x00 0x05 0x04 0x00 0x06 0x04 0x00 0x07 0x04 0x00 0x08 0x04 0x00 0x09 0x04 0x00 0x0a 0x04 0x00 0x0b 0x04 0x00 0x0c 0x04>;
				phandle = <0x13>;
			};

			gpa1-gpio-bank {
				gpio-controller;
				#gpio-cells = <0x02>;
				interrupt-controller;
				#interrupt-cells = <0x02>;
				interrupt-parent = <0x01>;
				interrupts = <0x00 0x0d 0x04 0x00 0x0e 0x04 0x00 0x0f 0x04 0x00 0x10 0x04 0x00 0x11 0x04 0x00 0x12 0x04 0x00 0x13 0x04 0x00 0x14 0x04>;
				phandle = <0x1d>;
			};

			gpa2-gpio-bank {
				gpio-controller;
				#gpio-cells = <0x02>;
				interrupt-controller;
				#interrupt-cells = <0x02>;
				interrupt-parent = <0x01>;
				interrupts = <0x00 0x15 0x04 0x00 0x16 0x04 0x00 0x17 0x04 0x00 0x18 0x04 0x00 0x19 0x04 0x00 0x1a 0x04 0x00 0x1b 0x04 0x00 0x1c 0x04>;
				phandle = <0x4d>;
			};

			gpa3-gpio-bank {
				gpio-controller;
				#gpio-cells = <0x02>;
				interrupt-controller;
				#interrupt-cells = <0x02>;
				interrupt-parent = <0x01>;
				interrupts = <0x00 0x1d 0x04 0x00 0x1e 0x04 0x00 0x1f 0x04 0x00 0x20 0x04 0x00 0x21 0x04 0x00 0x22 0x04 0x00 0x23 0x04 0x00 0x24 0x04>;
			};

			gpa4-gpio-bank {
				gpio-controller;
				#gpio-cells = <0x02>;
				interrupt-controller;
				#interrupt-cells = <0x02>;
				interrupt-parent = <0x01>;
				interrupts = <0x00 0x25 0x04 0x00 0x26 0x04>;
			};

			gpq0-gpio-bank {
				gpio-controller;
				#gpio-cells = <0x02>;
				interrupt-controller;
				#interrupt-cells = <0x02>;
			};

			etc0-gpio-bank {
				gpio-controller;
				#gpio-cells = <0x02>;
				interrupt-controller;
				#interrupt-cells = <0x02>;
			};

			key-volup-pins {
				samsung,pins = "gpa0-3";
				samsung,pin-function = <0x0f>;
				samsung,pin-pud = <0x00>;
				samsung,pin-drv = <0x00>;
				phandle = <0x49>;
			};

			key-voldown-pins {
				samsung,pins = "gpa0-4";
				samsung,pin-function = <0x0f>;
				samsung,pin-pud = <0x00>;
				samsung,pin-drv = <0x00>;
				phandle = <0x4a>;
			};

			key-wink-pins {
				samsung,pins = "gpa0-6";
				samsung,pin-function = <0x0f>;
				samsung,pin-pud = <0x00>;
				samsung,pin-drv = <0x00>;
				phandle = <0x4b>;
			};

			key-power-pins {
				samsung,pins = "gpa2-4";
				samsung,pin-function = <0x0f>;
				samsung,pin-pud = <0x00>;
				samsung,pin-drv = <0x00>;
				phandle = <0x4c>;
			};

			pmic-int {
				samsung,pins = "gpa1-6";
				samsung,pin-function = <0x0f>;
				samsung,pin-pud = <0x00>;
				samsung,pin-drv = <0x00>;
				phandle = <0x33>;
			};

			ts-int-pins {
				samsung,pins = "gpa1-0";
				samsung,pin-function = <0x0f>;
				samsung,pin-pud = <0x00>;
				samsung,pin-drv = <0x00>;
				phandle = <0x1e>;
			};

			s10-codec-irq {
				samsung,pins = "gpa2-2";
				samsung,pin-function = <0x0f>;
				samsung,pin-pud = <0x00>;
				phandle = <0x57>;
			};

			s10-uart-bt-bus {
				samsung,pins = "gpq0-0", "gpq0-1", "gpq0-2", "gpq0-3";
				samsung,pin-function = <0x02>;
				samsung,pin-pud = <0x03>;
				samsung,pin-drv = <0x00>;
				phandle = <0x96>;
			};

			s10-bt-hostwake {
				samsung,pins = "gpa2-3";
				samsung,pin-function = <0x0f>;
				samsung,pin-pud = <0x01>;
				phandle = <0x9a>;
			};

			s10-nfc-irq {
				samsung,pins = "gpa1-2";
				samsung,pin-function = <0x0f>;
				samsung,pin-pud = <0x00>;
				phandle = <0x9f>;
			};

			s10-shub-host-req {
				samsung,pins = "gpa1-7";
				samsung,pin-function = <0x0f>;
				samsung,pin-pud = <0x01>;
				samsung,pin-drv = <0x03>;
				phandle = <0xa6>;
			};

			s10-shub-int {
				samsung,pins = "gpa4-0";
				samsung,pin-function = <0x0f>;
				samsung,pin-pud = <0x00>;
				samsung,pin-drv = <0x03>;
				phandle = <0xa7>;
			};

			s10-shub-batch-wake {
				samsung,pins = "gpa0-5";
				samsung,pin-function = <0x01>;
				samsung,pin-pud = <0x00>;
				phandle = <0xa8>;
			};
		};

		system-controller@15860000 {
			compatible = "samsung,exynos9820-pmu", "samsung,exynos7-pmu", "syscon";
			reg = <0x15860000 0x10000>;
			google,pmu-intr-gen-syscon = <0x2a>;
			phandle = <0x21>;
			#clock-cells = <0x01>;
			clocks = <0x14>;
			clock-names = "clkout0";

			syscon-poweroff {
				compatible = "syscon-poweroff";
				regmap = <0x21>;
				offset = <0x30c>;
				mask = <0x100>;
				value = <0x00>;
			};

			syscon-reboot {
				compatible = "syscon-reboot";
				regmap = <0x21>;
				offset = <0x3a00>;
				mask = <0x02>;
			};

			reboot-mode {
				compatible = "syscon-reboot-mode";
				offset = <0x80c>;
				mode-download = <0x12345671>;
				mode-charging = <0x12345673>;
				mode-recovery = <0x12345674>;
				mode-bootloader = <0x1234567d>;
			};
		};

		power-domain@15861900 {
			compatible = "samsung,exynos9820-pd";
			reg = <0x15861900 0x20>;
			#power-domain-cells = <0x00>;
			label = "AUD";
			phandle = <0x60>;
		};

		power-domain@15861d00 {
			compatible = "samsung,exynos9820-pd";
			reg = <0x15861d00 0x20>;
			#power-domain-cells = <0x00>;
			label = "NPU0";
			phandle = <0x2b>;
		};

		power-domain@15861d80 {
			compatible = "samsung,exynos9820-pd";
			reg = <0x15861d80 0x20>;
			#power-domain-cells = <0x00>;
			power-domains = <0x2b>;
			label = "NPU1";
		};

		power-domain@15861e00 {
			compatible = "samsung,exynos9820-pd";
			reg = <0x15861e00 0x20>;
			#power-domain-cells = <0x00>;
			label = "DPU";
			status = "disabled";
		};

		power-domain@15861e80 {
			compatible = "samsung,exynos9820-pd";
			reg = <0x15861e80 0x20>;
			#power-domain-cells = <0x00>;
			label = "DSPM";
			phandle = <0x2c>;
		};

		power-domain@15861f00 {
			compatible = "samsung,exynos9820-pd";
			reg = <0x15861f00 0x20>;
			#power-domain-cells = <0x00>;
			power-domains = <0x2c>;
			label = "DSPS";
		};

		power-domain@15862100 {
			compatible = "samsung,exynos9820-pd";
			reg = <0x15862100 0x20>;
			#power-domain-cells = <0x00>;
			label = "G3D";
			phandle = <0x4f>;
		};

		power-domain@15862200 {
			compatible = "samsung,exynos9820-pd";
			reg = <0x15862200 0x20>;
			#power-domain-cells = <0x00>;
			label = "FSYS0A";
			status = "disabled";
		};

		power-domain@15862300 {
			compatible = "samsung,exynos9820-pd";
			reg = <0x15862300 0x20>;
			#power-domain-cells = <0x00>;
			label = "G2D";
		};

		power-domain@15862400 {
			compatible = "samsung,exynos9820-pd";
			reg = <0x15862400 0x20>;
			#power-domain-cells = <0x00>;
			label = "ISPHQ";
		};

		power-domain@15862480 {
			compatible = "samsung,exynos9820-pd";
			reg = <0x15862480 0x20>;
			#power-domain-cells = <0x00>;
			label = "ISPLP";
			phandle = <0x2d>;
		};

		power-domain@15862500 {
			compatible = "samsung,exynos9820-pd";
			reg = <0x15862500 0x20>;
			#power-domain-cells = <0x00>;
			label = "ISPPRE";
			phandle = <0x72>;
		};

		power-domain@15862580 {
			compatible = "samsung,exynos9820-pd";
			reg = <0x15862580 0x20>;
			#power-domain-cells = <0x00>;
			label = "IVA";
		};

		power-domain@15862600 {
			compatible = "samsung,exynos9820-pd";
			reg = <0x15862600 0x20>;
			#power-domain-cells = <0x00>;
			label = "MFC";
		};

		power-domain@15862a80 {
			compatible = "samsung,exynos9820-pd";
			reg = <0x15862a80 0x20>;
			#power-domain-cells = <0x00>;
			label = "VTS";
		};

		power-domain@15862b00 {
			compatible = "samsung,exynos9820-pd";
			reg = <0x15862b00 0x20>;
			#power-domain-cells = <0x00>;
			power-domains = <0x2d>;
			label = "VRA2";
		};

		syscon@15870000 {
			compatible = "samsung,exynos9820-pmu-intr-gen", "syscon";
			reg = <0x15870000 0x1000>;
			phandle = <0x2a>;
		};

		mailbox@15900000 {
			compatible = "google,gs101-mbox";
			reg = <0x15900000 0x1000>;
			clocks = <0x29 0x20>;
			clock-names = "pclk";
			interrupts = <0x00 0x28 0x04>;
			#mbox-cells = <0x00>;
			phandle = <0x11>;
		};

		clock-controller@15c00000 {
			compatible = "samsung,exynos9820-cmu-cmgp";
			reg = <0x15c00000 0x10000>;
			#clock-cells = <0x01>;
			clock-names = "oscclk", "bus";
			clocks = <0x14 0x29 0x07>;
			samsung,sysreg = <0x2e>;
			phandle = <0x2f>;
		};

		syscon@15c20000 {
			compatible = "samsung,exynos9820-cmgp-sysreg", "syscon";
			reg = <0x15c20000 0x10000>;
			clocks = <0x2f 0x30>;
			phandle = <0x2e>;
		};

		pinctrl@15c30000 {
			compatible = "samsung,exynos9820-pinctrl";
			reg = <0x15c30000 0x1000>;
			clocks = <0x2f 0x19>;
			clock-names = "pclk";

			wakeup-interrupt-controller {
				compatible = "samsung,exynos7-wakeup-eint";
			};

			gpm0-gpio-bank {
				gpio-controller;
				#gpio-cells = <0x02>;
				interrupt-controller;
				#interrupt-cells = <0x02>;
				interrupt-parent = <0x01>;
				interrupts = <0x00 0x55 0x04>;
			};

			gpm1-gpio-bank {
				gpio-controller;
				#gpio-cells = <0x02>;
				interrupt-controller;
				#interrupt-cells = <0x02>;
				interrupt-parent = <0x01>;
				interrupts = <0x00 0x56 0x04>;
			};

			gpm2-gpio-bank {
				gpio-controller;
				#gpio-cells = <0x02>;
				interrupt-controller;
				#interrupt-cells = <0x02>;
				interrupt-parent = <0x01>;
				interrupts = <0x00 0x57 0x04>;
			};

			gpm3-gpio-bank {
				gpio-controller;
				#gpio-cells = <0x02>;
				interrupt-controller;
				#interrupt-cells = <0x02>;
				interrupt-parent = <0x01>;
				interrupts = <0x00 0x58 0x04>;
			};

			gpm4-gpio-bank {
				gpio-controller;
				#gpio-cells = <0x02>;
				interrupt-controller;
				#interrupt-cells = <0x02>;
				interrupt-parent = <0x01>;
				interrupts = <0x00 0x59 0x04>;
			};

			gpm5-gpio-bank {
				gpio-controller;
				#gpio-cells = <0x02>;
				interrupt-controller;
				#interrupt-cells = <0x02>;
				interrupt-parent = <0x01>;
				interrupts = <0x00 0x5a 0x04>;
			};

			gpm6-gpio-bank {
				gpio-controller;
				#gpio-cells = <0x02>;
				interrupt-controller;
				#interrupt-cells = <0x02>;
				interrupt-parent = <0x01>;
				interrupts = <0x00 0x5b 0x04>;
			};

			gpm7-gpio-bank {
				gpio-controller;
				#gpio-cells = <0x02>;
				interrupt-controller;
				#interrupt-cells = <0x02>;
				interrupt-parent = <0x01>;
				interrupts = <0x00 0x5c 0x04>;
			};

			gpm8-gpio-bank {
				gpio-controller;
				#gpio-cells = <0x02>;
				interrupt-controller;
				#interrupt-cells = <0x02>;
				interrupt-parent = <0x01>;
				interrupts = <0x00 0x5d 0x04>;
				phandle = <0x97>;
			};

			gpm9-gpio-bank {
				gpio-controller;
				#gpio-cells = <0x02>;
				interrupt-controller;
				#interrupt-cells = <0x02>;
				interrupt-parent = <0x01>;
				interrupts = <0x00 0x5e 0x04>;
			};

			gpm10-gpio-bank {
				gpio-controller;
				#gpio-cells = <0x02>;
				interrupt-controller;
				#interrupt-cells = <0x02>;
				interrupt-parent = <0x01>;
				interrupts = <0x00 0x5f 0x04>;
			};

			gpm11-gpio-bank {
				gpio-controller;
				#gpio-cells = <0x02>;
				interrupt-controller;
				#interrupt-cells = <0x02>;
				interrupt-parent = <0x01>;
				interrupts = <0x00 0x60 0x04>;
			};

			gpm12-gpio-bank {
				gpio-controller;
				#gpio-cells = <0x02>;
				interrupt-controller;
				#interrupt-cells = <0x02>;
				interrupt-parent = <0x01>;
				interrupts = <0x00 0x61 0x04>;
			};

			gpm13-gpio-bank {
				gpio-controller;
				#gpio-cells = <0x02>;
				interrupt-controller;
				#interrupt-cells = <0x02>;
				interrupt-parent = <0x01>;
				interrupts = <0x00 0x62 0x04>;
			};

			gpm14-gpio-bank {
				gpio-controller;
				#gpio-cells = <0x02>;
				interrupt-controller;
				#interrupt-cells = <0x02>;
				interrupt-parent = <0x01>;
				interrupts = <0x00 0x63 0x04>;
			};

			gpm15-gpio-bank {
				gpio-controller;
				#gpio-cells = <0x02>;
				interrupt-controller;
				#interrupt-cells = <0x02>;
				interrupt-parent = <0x01>;
				interrupts = <0x00 0x64 0x04>;
			};

			gpm16-gpio-bank {
				gpio-controller;
				#gpio-cells = <0x02>;
				interrupt-controller;
				#interrupt-cells = <0x02>;
				interrupt-parent = <0x01>;
				interrupts = <0x00 0x65 0x04>;
			};

			gpm17-gpio-bank {
				gpio-controller;
				#gpio-cells = <0x02>;
				interrupt-controller;
				#interrupt-cells = <0x02>;
				interrupt-parent = <0x01>;
				interrupts = <0x00 0x66 0x04>;
			};

			gpm18-gpio-bank {
				gpio-controller;
				#gpio-cells = <0x02>;
				interrupt-controller;
				#interrupt-cells = <0x02>;
				interrupt-parent = <0x01>;
				interrupts = <0x00 0x67 0x04>;
			};

			gpm19-gpio-bank {
				gpio-controller;
				#gpio-cells = <0x02>;
				interrupt-controller;
				#interrupt-cells = <0x02>;
				interrupt-parent = <0x01>;
				interrupts = <0x00 0x68 0x04>;
			};

			gpm20-gpio-bank {
				gpio-controller;
				#gpio-cells = <0x02>;
				interrupt-controller;
				#interrupt-cells = <0x02>;
				interrupt-parent = <0x01>;
				interrupts = <0x00 0x69 0x04>;
			};

			gpm21-gpio-bank {
				gpio-controller;
				#gpio-cells = <0x02>;
				interrupt-controller;
				#interrupt-cells = <0x02>;
				interrupt-parent = <0x01>;
				interrupts = <0x00 0x6a 0x04>;
			};

			gpm22-gpio-bank {
				gpio-controller;
				#gpio-cells = <0x02>;
				interrupt-controller;
				#interrupt-cells = <0x02>;
				interrupt-parent = <0x01>;
				interrupts = <0x00 0x6b 0x04>;
			};

			gpm23-gpio-bank {
				gpio-controller;
				#gpio-cells = <0x02>;
				interrupt-controller;
				#interrupt-cells = <0x02>;
				interrupt-parent = <0x01>;
				interrupts = <0x00 0x6c 0x04>;
			};

			gpm24-gpio-bank {
				gpio-controller;
				#gpio-cells = <0x02>;
				interrupt-controller;
				#interrupt-cells = <0x02>;
				interrupt-parent = <0x01>;
				interrupts = <0x00 0x6d 0x04>;
				phandle = <0x5e>;
			};

			gpm25-gpio-bank {
				gpio-controller;
				#gpio-cells = <0x02>;
				interrupt-controller;
				#interrupt-cells = <0x02>;
				interrupt-parent = <0x01>;
				interrupts = <0x00 0x6e 0x04>;
			};

			gpm26-gpio-bank {
				gpio-controller;
				#gpio-cells = <0x02>;
				interrupt-controller;
				#interrupt-cells = <0x02>;
				interrupt-parent = <0x01>;
				interrupts = <0x00 0x6f 0x04>;
			};

			gpm27-gpio-bank {
				gpio-controller;
				#gpio-cells = <0x02>;
				interrupt-controller;
				#interrupt-cells = <0x02>;
				interrupt-parent = <0x01>;
				interrupts = <0x00 0x70 0x04>;
			};

			gpm28-gpio-bank {
				gpio-controller;
				#gpio-cells = <0x02>;
				interrupt-controller;
				#interrupt-cells = <0x02>;
				interrupt-parent = <0x01>;
				interrupts = <0x00 0x71 0x04>;
			};

			gpm29-gpio-bank {
				gpio-controller;
				#gpio-cells = <0x02>;
				interrupt-controller;
				#interrupt-cells = <0x02>;
				interrupt-parent = <0x01>;
				interrupts = <0x00 0x72 0x04>;
			};

			gpm30-gpio-bank {
				gpio-controller;
				#gpio-cells = <0x02>;
				interrupt-controller;
				#interrupt-cells = <0x02>;
				interrupt-parent = <0x01>;
				interrupts = <0x00 0x73 0x04>;
			};

			gpm31-gpio-bank {
				gpio-controller;
				#gpio-cells = <0x02>;
				interrupt-controller;
				#interrupt-cells = <0x02>;
				interrupt-parent = <0x01>;
				interrupts = <0x00 0x74 0x04>;
			};

			hsi2c45-bus-pins {
				samsung,pins = "gpm12-0", "gpm13-0";
				samsung,pin-function = <0x02>;
				samsung,pin-pud = <0x00>;
				samsung,pin-drv = <0x00>;
				phandle = <0x30>;
			};

			s10-amp-irq {
				samsung,pins = "gpm24-0";
				samsung,pin-function = <0x00>;
				samsung,pin-pud = <0x00>;
				phandle = <0x5d>;
			};

			s10-pmic-i2c {
				samsung,pins = "gpm6-0", "gpm7-0";
				samsung,pin-function = <0x03>;
				samsung,pin-pud = <0x00>;
				samsung,pin-drv = <0x00>;
				phandle = <0x8f>;
			};

			s10-bt-en {
				samsung,pins = "gpm8-0";
				samsung,pin-function = <0x01>;
				samsung,pin-pud = <0x00>;
				samsung,pin-con-pdn = <0x03>;
				samsung,pin-pud-pdn = <0x00>;
				phandle = <0x98>;
			};
		};

		usi@15d600c0 {
			compatible = "samsung,exynos850-usi";
			reg = <0x15d600c0 0x20>;
			ranges;
			clock-names = "pclk", "ipclk";
			clocks = <0x2f 0x38 0x2f 0x37>;
			#address-cells = <0x01>;
			#size-cells = <0x01>;
			samsung,sysreg = <0x2e 0x2030>;
			status = "okay";
			samsung,mode = <0x03>;

			i2c@15d60000 {
				compatible = "samsung,exynosautov9-hsi2c";
				reg = <0x15d60000 0xc0>;
				clock-names = "hsi2c", "hsi2c_pclk";
				clocks = <0x2f 0x37 0x2f 0x38>;
				interrupts = <0x00 0x52 0x04>;
				pinctrl-0 = <0x30>;
				pinctrl-names = "default";
				#address-cells = <0x01>;
				#size-cells = <0x00>;
				status = "okay";
				clock-frequency = <0x61a80>;

				fuel-gauge@36 {
					reg = <0x36>;
					compatible = "maxim,max77705-battery";
					power-supplies = <0x31>;
					maxim,rsns-microohm = <0x1388>;
					interrupt-parent = <0x32>;
					interrupts = <0x02>;
				};

				pmic@66 {
					compatible = "maxim,max77705";
					reg = <0x66>;
					interrupts-extended = <0x1d 0x06 0x08>;
					interrupt-controller;
					#interrupt-cells = <0x01>;
					pinctrl-0 = <0x33>;
					pinctrl-names = "default";
					phandle = <0x32>;

					haptic {
						compatible = "maxim,max77705-haptic";
						haptic-supply = <0x34>;
						pwms = <0x35 0x01 0xbebc 0x00>;
					};
				};

				charger@69 {
					reg = <0x69>;
					compatible = "maxim,max77705-charger";
					monitored-battery = <0x36>;
					interrupt-parent = <0x32>;
					interrupts = <0x00>;
					phandle = <0x31>;
				};

				typec@25 {
					compatible = "maxim,max77705-usbc";
					reg = <0x25>;
					interrupt-parent = <0x32>;
					interrupts = <0x03>;
					maxim,charger = <0x31>;

					connector {
						compatible = "usb-c-connector";
						label = "USB-C";
						power-role = "sink";
						data-role = "device";
						sink-pdos = <0x1401912c 0x2d0c8>;
						op-sink-microwatt = <0xe4e1c0>;
					};
				};
			};
		};

		clock-controller@18400000 {
			compatible = "samsung,exynos9820-cmu-g3d";
			reg = <0x18400000 0x10000>;
			#clock-cells = <0x01>;
			clock-names = "oscclk";
			clocks = <0x14>;
			samsung,sysreg = <0x37>;
		};

		syscon@18420000 {
			compatible = "samsung,exynos9820-g3d-sysreg", "syscon";
			reg = <0x18420000 0x10000>;
			phandle = <0x37>;
		};

		pinctrl@18c60000 {
			compatible = "samsung,exynos9820-pinctrl";
			reg = <0x18c60000 0x1000>;
			power-domains = <0x60>;

			gpb0-gpio-bank {
				gpio-controller;
				#gpio-cells = <0x02>;
				interrupt-controller;
				#interrupt-cells = <0x02>;
			};

			gpb1-gpio-bank {
				gpio-controller;
				#gpio-cells = <0x02>;
				interrupt-controller;
				#interrupt-cells = <0x02>;
			};

			gpb2-gpio-bank {
				gpio-controller;
				#gpio-cells = <0x02>;
				interrupt-controller;
				#interrupt-cells = <0x02>;
			};
		};

		clock-controller@19000000 {
			compatible = "samsung,exynos9820-cmu-dpu";
			reg = <0x19000000 0x10000>;
			#clock-cells = <0x01>;
			clock-names = "oscclk", "bus";
			clocks = <0x14 0x15 0x6f>;
			samsung,sysreg = <0x38>;
			phandle = <0x39>;
		};

		syscon@19010000 {
			compatible = "samsung,exynos9820-dpu-sysreg", "syscon";
			reg = <0x19010000 0x10000>;
			clocks = <0x39 0x3f>;
			phandle = <0x38>;
		};

		syscon@1a020000 {
			compatible = "samsung,exynos9820-core-sysreg", "syscon";
			reg = <0x1a020000 0x10000>;
			phandle = <0x3a>;
		};

		clock-controller@1a030000 {
			compatible = "samsung,exynos9820-cmu-core";
			reg = <0x1a030000 0x10000>;
			#clock-cells = <0x01>;
			clock-names = "oscclk", "bus";
			clocks = <0x14 0x15 0x4b>;
			samsung,sysreg = <0x3a>;
		};

		clock-controller@1a200000 {
			compatible = "samsung,exynos9820-cmu-busc";
			reg = <0x1a200000 0x10000>;
			#clock-cells = <0x01>;
			clock-names = "oscclk", "bus";
			clocks = <0x14 0x15 0x44>;
			samsung,sysreg = <0x3b>;
			phandle = <0x3c>;
		};

		syscon@1a220000 {
			compatible = "samsung,exynos9820-busc-sysreg", "syscon";
			reg = <0x1a220000 0x10000>;
			clocks = <0x3c 0x50>;
			phandle = <0x3b>;
		};

		clock-controller@1a240000 {
			compatible = "samsung,exynos9820-cmu-top";
			reg = <0x1a240000 0x10000>;
			#clock-cells = <0x01>;
			clock-names = "oscclk";
			clocks = <0x14>;
			phandle = <0x15>;
		};

		clock-controller@1bc00000 {
			compatible = "samsung,exynos9820-cmu-mif";
			reg = <0x1bc00000 0x10000>;
			#clock-cells = <0x01>;
			clock-names = "oscclk", "bus";
			clocks = <0x14 0x15 0x64>;
			samsung,sysreg = <0x3d>;
		};

		syscon@1bc20000 {
			compatible = "samsung,exynos9820-mif0-sysreg", "syscon";
			reg = <0x1bc20000 0x10000>;
			phandle = <0x3d>;
		};

		clock-controller@1bd00000 {
			compatible = "samsung,exynos9820-cmu-mif";
			reg = <0x1bd00000 0x10000>;
			#clock-cells = <0x01>;
			clock-names = "oscclk", "bus";
			clocks = <0x14 0x15 0x64>;
			samsung,sysreg = <0x3e>;
		};

		syscon@1bd20000 {
			compatible = "samsung,exynos9820-mif1-sysreg", "syscon";
			reg = <0x1bd20000 0x10000>;
			phandle = <0x3e>;
		};

		clock-controller@1be00000 {
			compatible = "samsung,exynos9820-cmu-mif";
			reg = <0x1be00000 0x10000>;
			#clock-cells = <0x01>;
			clock-names = "oscclk", "bus";
			clocks = <0x14 0x15 0x64>;
			samsung,sysreg = <0x3f>;
		};

		syscon@1be20000 {
			compatible = "samsung,exynos9820-mif2-sysreg", "syscon";
			reg = <0x1be20000 0x10000>;
			phandle = <0x3f>;
		};

		clock-controller@1bf00000 {
			compatible = "samsung,exynos9820-cmu-mif";
			reg = <0x1bf00000 0x10000>;
			#clock-cells = <0x01>;
			clock-names = "oscclk", "bus";
			clocks = <0x14 0x15 0x64>;
			samsung,sysreg = <0x40>;
		};

		syscon@1bf20000 {
			compatible = "samsung,exynos9820-mif3-sysreg", "syscon";
			reg = <0x1bf20000 0x10000>;
			phandle = <0x40>;
		};

		syscon@1d000000 {
			compatible = "samsung,exynos9820-cpucl0-sysreg", "syscon";
			reg = <0x1d000000 0x10000>;
			phandle = <0x41>;
		};

		clock-controller@1d020000 {
			compatible = "samsung,exynos9820-cmu-cpucl0";
			reg = <0x1d020000 0x10000>;
			#clock-cells = <0x01>;
			clock-names = "oscclk";
			clocks = <0x14>;
			samsung,sysreg = <0x41>;
		};

		syscon@1d100000 {
			compatible = "samsung,exynos9820-cpucl2-sysreg", "syscon";
			reg = <0x1d100000 0x10000>;
			phandle = <0x42>;
		};

		clock-controller@1d120000 {
			compatible = "samsung,exynos9820-cmu-cpucl2";
			reg = <0x1d120000 0x10000>;
			#clock-cells = <0x01>;
			clock-names = "oscclk";
			clocks = <0x14>;
			samsung,sysreg = <0x42>;
		};

		gpu@18500000 {
			compatible = "samsung,exynos9820-mali", "arm,mali-bifrost";
			reg = <0x18500000 0x5000>;
			interrupts = <0x00 0x120 0x04 0x00 0x11f 0x04 0x00 0x121 0x04>;
			interrupt-names = "job", "mmu", "gpu";
			clocks = <0x0a 0x0a>;
			clock-names = "gpu";
			power-domains = <0x4f>;
			status = "okay";
			operating-points-v2 = <0x63>;
			#cooling-cells = <0x02>;
			phandle = <0x65>;
		};

		pcie@13ed0000 {
			compatible = "samsung,exynos9820-pcie-test";
			device_type = "pci";
			reg = <0x13ed0000 0x1000 0x13ef0000 0x1000 0x13f00000 0x1000 0x13ee0000 0x200 0x14ffe000 0x2000>;
			reg-names = "elbi", "phy", "dbi", "pcs", "config";
			#address-cells = <0x03>;
			#size-cells = <0x02>;
			#interrupt-cells = <0x01>;
			bus-range = <0x00 0xff>;
			ranges = <0x82000000 0x00 0x14000000 0x14000000 0x00 0xff0000>;
			interrupts = <0x00 0xfd 0x04>;
			interrupt-names = "pcie";
			interrupt-map-mask = <0x00 0x00 0x00 0x07>;
			interrupt-map = <0x00 0x00 0x00 0x01 0x01 0x00 0xfd 0x04>;
			clocks = <0x26 0x0b 0x26 0x17 0x26 0x18 0x26 0x19 0x26 0x1a 0x26 0x1b 0x26 0x1c 0x26 0x1d>;
			clock-names = "ref", "dbi", "phy-apb", "master", "ctrl-apb", "pcs-apb", "slave", "ia";
			samsung,sysreg = <0x25>;
			samsung,pmu = <0x21>;
			reset-gpios = <0x50 0x02 0x01>;
			wlan-enable-gpios = <0x51 0x05 0x00>;
			pinctrl-names = "default";
			pinctrl-0 = <0x52>;
			num-lanes = <0x01>;
			max-link-speed = <0x01>;
			status = "okay";
		};

		usi@104700c0 {
			compatible = "samsung,exynos850-usi";
			reg = <0x104700c0 0x20>;
			ranges;
			#address-cells = <0x01>;
			#size-cells = <0x01>;
			clock-names = "pclk", "ipclk";
			clocks = <0x19 0x39 0x19 0x38>;
			samsung,sysreg = <0x18 0x100c>;
			samsung,mode = <0x02>;
			status = "okay";

			spi@10470000 {
				compatible = "samsung,exynos850-spi";
				reg = <0x10470000 0x30>;
				interrupts = <0x00 0x180 0x04>;
				clock-names = "spi", "spi_busclk0";
				clocks = <0x19 0x39 0x19 0x38>;
				num-cs = <0x01>;
				cs-gpios = <0x53 0x07 0x01>;
				pinctrl-names = "default";
				pinctrl-0 = <0x54 0x55 0x56 0x57>;
				#address-cells = <0x01>;
				#size-cells = <0x00>;
				status = "okay";

				codec@0 {
					compatible = "cirrus,cs47l93";
					reg = <0x00>;
					spi-max-frequency = <0x4c4b40>;
					interrupts-extended = <0x4d 0x02 0x08>;
					interrupt-controller;
					#interrupt-cells = <0x02>;
					gpio-controller;
					#gpio-cells = <0x02>;
					reset-gpios = <0x4e 0x00 0x01>;
					AVDD-supply = <0x58>;
					DBVDD1-supply = <0x58>;
					CPVDD1-supply = <0x58>;
					CPVDD2-supply = <0x59>;
					DCVDD-supply = <0x59>;
				};
			};
		};

		usi@109a00c0 {
			compatible = "samsung,exynos850-usi";
			reg = <0x109a00c0 0x20>;
			ranges;
			#address-cells = <0x01>;
			#size-cells = <0x01>;
			clock-names = "pclk", "ipclk";
			clocks = <0x5a 0x11 0x5a 0x10>;
			samsung,sysreg = <0x1f 0x1050>;
			samsung,mode = <0x03>;
			status = "okay";

			i2c@109a0000 {
				compatible = "samsung,exynos9820-hsi2c";
				reg = <0x109a0000 0xc0>;
				clock-names = "hsi2c", "hsi2c_pclk";
				clocks = <0x5a 0x10 0x5a 0x11>;
				interrupts = <0x00 0x1ac 0x04>;
				pinctrl-names = "default";
				pinctrl-0 = <0x5b 0x5c 0x5d>;
				#address-cells = <0x01>;
				#size-cells = <0x00>;
				clock-frequency = <0x61a80>;
				status = "okay";

				amplifier@40 {
					compatible = "cirrus,cs35l40";
					reg = <0x40>;
					#sound-dai-cells = <0x01>;
					sound-name-prefix = "Bottom";
					interrupts-extended = <0x5e 0x00 0x08>;
					reset-gpios = <0x5f 0x01 0x00>;
					cirrus,boost-type = <0x00>;
					cirrus,boost-peak-milliamp = <0x1004>;
					cirrus,boost-ind-nanohenry = <0x3e8>;
					cirrus,boost-cap-microfarad = <0x0a>;
					cirrus,asp-sdout-hiz = <0x03>;
					cirrus,gpio2-src-select = <0x04>;
					cirrus,gpio2-output-enable;
					phandle = <0x61>;
				};

				amplifier@41 {
					compatible = "cirrus,cs35l40";
					reg = <0x41>;
					#sound-dai-cells = <0x01>;
					sound-name-prefix = "Receiver";
					interrupts-extended = <0x5e 0x00 0x08>;
					reset-gpios = <0x5f 0x02 0x00>;
					cirrus,boost-type = <0x00>;
					cirrus,boost-peak-milliamp = <0x1004>;
					cirrus,boost-ind-nanohenry = <0x3e8>;
					cirrus,boost-cap-microfarad = <0x0a>;
					cirrus,asp-sdout-hiz = <0x03>;
					cirrus,gpio2-src-select = <0x04>;
					cirrus,gpio2-output-enable;
					phandle = <0x62>;
				};
			};
		};

		audio-probe@18c00000 {
			compatible = "samsung,exynos9820-aud-probe-test";
			reg = <0x18c00000 0x8000 0x18c50000 0x100>;
			reg-names = "cmu", "abox";
			clock-names = "top";
			clocks = <0x15 0x43>;
			power-domains = <0x60>;
		};

		abox-speaker-card {
			compatible = "samsung,exynos9820-abox-s10-test";
			samsung,amplifiers = <0x61 0x62>;
		};

		usi@109200c0 {
			compatible = "samsung,exynos850-usi";
			reg = <0x109200c0 0x20>;
			ranges;
			clock-names = "pclk", "ipclk";
			clocks = <0x5a 0x07 0x5a 0x06>;
			#address-cells = <0x01>;
			#size-cells = <0x01>;
			samsung,sysreg = <0x1f 0x1038>;
			samsung,mode = <0x03>;
			status = "okay";

			i2c@10920000 {
				compatible = "samsung,exynosautov9-hsi2c";
				reg = <0x10920000 0xc0>;
				clock-names = "hsi2c", "hsi2c_pclk";
				clocks = <0x5a 0x06 0x5a 0x07>;
				interrupts = <0x00 0x1a6 0x04>;
				pinctrl-names = "default";
				pinctrl-0 = <0x66>;
				#address-cells = <0x01>;
				#size-cells = <0x00>;
				clock-frequency = <0x186a0>;
				status = "okay";

				pmic@59 {
					compatible = "samsung,s2mpb02-camera-test";
					reg = <0x59>;

					regulators {

						s2mpb02-buck2 {
							regulator-name = "VDD_EXT_1P3_PB02";
							regulator-min-microvolt = <0x13d620>;
							regulator-max-microvolt = <0x13d620>;
							phandle = <0x6c>;
						};

						s2mpb02-ldo4 {
							regulator-name = "VDDD_1.05V_WIDESUB";
							regulator-min-microvolt = <0x100590>;
							regulator-max-microvolt = <0x100590>;
							phandle = <0x6e>;
						};

						s2mpb02-ldo6 {
							regulator-name = "VDDIO_1.8V_VT";
							regulator-min-microvolt = <0x1b7740>;
							regulator-max-microvolt = <0x1b7740>;
							phandle = <0x6f>;
						};

						s2mpb02-ldo8 {
							regulator-name = "VDDIO_1.8V_WIDESUB";
							regulator-min-microvolt = <0x1b7740>;
							regulator-max-microvolt = <0x1b7740>;
							phandle = <0x70>;
						};

						s2mpb02-ldo15 {
							regulator-name = "VDDA_2.8V_WIDESUB";
							regulator-min-microvolt = <0x2ab980>;
							regulator-max-microvolt = <0x2ab980>;
							phandle = <0x6d>;
						};

						s2mpb02-ldo3 {
							regulator-name = "VDDD_1.05V_SUB";
							regulator-min-microvolt = <0x100590>;
							regulator-max-microvolt = <0x100590>;
							phandle = <0x7f>;
						};

						s2mpb02-ldo5 {
							regulator-name = "VDDD_1.05V_VT";
							regulator-min-microvolt = <0x100590>;
							regulator-max-microvolt = <0x100590>;
							phandle = <0x89>;
						};

						s2mpb02-ldo7 {
							regulator-name = "VDDIO_1.8V_SUB";
							regulator-min-microvolt = <0x1b7740>;
							regulator-max-microvolt = <0x1b7740>;
							phandle = <0x80>;
						};

						s2mpb02-ldo11 {
							regulator-name = "VDDA_2.8V_SUB";
							regulator-min-microvolt = <0x2ab980>;
							regulator-max-microvolt = <0x2ab980>;
							phandle = <0x7e>;
						};

						s2mpb02-ldo12 {
							regulator-name = "VDDAF_2.8V_SUB";
							regulator-min-microvolt = <0x2ab980>;
							regulator-max-microvolt = <0x2ab980>;
							phandle = <0x8d>;
						};

						s2mpb02-ldo13 {
							regulator-name = "VDDA_2.95V_VT";
							regulator-min-microvolt = <0x2d0370>;
							regulator-max-microvolt = <0x2d0370>;
							phandle = <0x88>;
						};

						s2mpb02-ldo16 {
							regulator-name = "VDDAF_2.8V_VT";
							regulator-min-microvolt = <0x2ab980>;
							regulator-max-microvolt = <0x2ab980>;
							phandle = <0x95>;
						};

						s2mpb02-ldo10 {
							regulator-name = "VDDD_1.8V_OIS";
							regulator-min-microvolt = <0x1b7740>;
							regulator-max-microvolt = <0x1b7740>;
						};

						s2mpb02-ldo14 {
							phandle = <0xb5>;
							regulator-name = "VDDAF_COMMON_CAM";
							regulator-min-microvolt = <0x325aa0>;
							regulator-max-microvolt = <0x325aa0>;
						};

						s2mpb02-buck1 {
							regulator-name = "S2MPB02_BUCK1";
							regulator-min-microvolt = <0x13d620>;
							regulator-max-microvolt = <0x13d620>;
							regulator-always-on;
						};
					};
				};
			};
		};

		camera-clock@1a243014 {
			compatible = "samsung,exynos9820-cis3-clock-test";
			reg = <0x1a243014 0x04>;
			#clock-cells = <0x00>;
			clocks = <0x15 0x48>;
			phandle = <0x6b>;
		};

		usi@108700c0 {
			compatible = "samsung,exynos850-usi";
			reg = <0x108700c0 0x20>;
			ranges;
			#address-cells = <0x01>;
			#size-cells = <0x01>;
			clock-names = "pclk", "ipclk";
			clocks = <0x5a 0x09 0x5a 0x08>;
			samsung,sysreg = <0x1f 0x100c>;
			samsung,mode = <0x03>;
			samsung,clkreq-on;
			status = "okay";

			i2c@10870000 {
				compatible = "samsung,exynos9820-hsi2c";
				reg = <0x10870000 0xc0>;
				clock-names = "hsi2c", "hsi2c_pclk";
				clocks = <0x5a 0x08 0x5a 0x09>;
				interrupts = <0x00 0x19b 0x04>;
				pinctrl-names = "default", "camera-on";
				pinctrl-0 = <0x67 0x68>;
				pinctrl-1 = <0x69 0x6a>;
				#address-cells = <0x01>;
				#size-cells = <0x00>;
				clock-frequency = <0x186a0>;
				status = "okay";

				sensor@2d {
					compatible = "samsung,s5k3p9";
					reg = <0x2d>;
					reset-gpios = <0x51 0x03 0x01>;
					clocks = <0x6b>;
					clock-names = "mclk";
					pre-supply = <0x6c>;
					avdd-supply = <0x6d>;
					dvdd-supply = <0x6e>;
					vtio-supply = <0x6f>;
					iovdd-supply = <0x70>;
					orientation = <0x01>;
					rotation = <0x10e>;

					port {

						endpoint {
							remote-endpoint = <0x71>;
							data-lanes = <0x01 0x02 0x03 0x04>;
							link-frequencies = <0x00 0x3d36c6c0>;
							phandle = <0x74>;
						};
					};
				};
			};
		};

		camera-isppre-hold {
			compatible = "samsung,exynos9820-isppre-hold-test";
			power-domains = <0x72>;
		};

		clock-controller@17000000 {
			compatible = "samsung,exynos9820-isppre-clock-test";
			reg = <0x17000000 0x8000>;
			#clock-cells = <0x01>;
			clock-names = "bus";
			clocks = <0x15 0x60>;
			power-domains = <0x72>;
			phandle = <0x73>;
		};

		camera-csis@17040000 {
			compatible = "samsung,exynos9820-csis";
			reg = <0x17040000 0x1000 0x170e0000 0x100 0x17020500 0x04 0x19162b00 0x500 0x170b0000 0x500>;
			reg-names = "csis", "dma-top", "phy-reset", "phy", "dma";
			interrupts = <0x00 0x136 0x04 0x00 0x13c 0x04>;
			interrupt-names = "csis", "dma";
			samsung,pmu-syscon = <0x21>;
			samsung,pmu-phy-offset = <0x730>;
			samsung,phy-reset-bit = <0x02>;
			power-domains = <0x72>;
			clock-names = "csis", "dma", "mmu", "bus";
			clocks = <0x73 0x03 0x73 0x04 0x73 0x05 0x15 0x60>;

			ports {
				#address-cells = <0x01>;
				#size-cells = <0x00>;

				port@0 {
					reg = <0x00>;

					endpoint {
						remote-endpoint = <0x74>;
						data-lanes = <0x01 0x02 0x03 0x04>;
						phandle = <0x71>;
					};
				};
			};
		};

		camera-clock@1a243008 {
			compatible = "samsung,exynos9820-cis-clock-test";
			reg = <0x1a243008 0x04>;
			#clock-cells = <0x00>;
			clocks = <0x15 0x45>;
			phandle = <0x7b>;
			pinctrl-names = "default", "active";
			pinctrl-0 = <0x77>;
			pinctrl-1 = <0x79>;
		};

		camera-clock@1a24300c {
			compatible = "samsung,exynos9820-cis-clock-test";
			reg = <0x1a24300c 0x04>;
			#clock-cells = <0x00>;
			clocks = <0x15 0x46>;
			phandle = <0x87>;
		};

		camera-subcam-mux {
			compatible = "gpio-mux";
			#mux-control-cells = <0x00>;
			mux-gpios = <0x75 0x03 0x00>;
			phandle = <0x7c>;
		};

		usi@108d00c0 {
			compatible = "samsung,exynos850-usi";
			reg = <0x108d00c0 0x20>;
			ranges;
			#address-cells = <0x01>;
			#size-cells = <0x01>;
			clock-names = "pclk", "ipclk";
			clocks = <0x5a 0x17 0x5a 0x16>;
			samsung,sysreg = <0x1f 0x1024>;
			samsung,mode = <0x03>;
			samsung,clkreq-on;
			status = "okay";

			i2c@108d0000 {
				compatible = "samsung,exynos9820-hsi2c";
				reg = <0x108d0000 0xc0>;
				clock-names = "hsi2c", "hsi2c_pclk";
				clocks = <0x5a 0x16 0x5a 0x17>;
				interrupts = <0x00 0x1a1 0x04>;
				pinctrl-names = "default", "camera-on";
				pinctrl-0 = <0x76>;
				pinctrl-1 = <0x78>;
				#address-cells = <0x01>;
				#size-cells = <0x00>;
				clock-frequency = <0x186a0>;
				status = "okay";

				sensor@2d {
					compatible = "samsung,s5k3m3";
					reg = <0x2d>;
					reset-gpios = <0x7a 0x00 0x01>;
					clocks = <0x7b>;
					clock-names = "mclk";
					mux-controls = <0x7c>;
					lens-focus = <0x7d>;
					pre-supply = <0x6c>;
					avdd-supply = <0x7e>;
					dvdd-supply = <0x7f>;
					iovdd-supply = <0x80>;
					orientation = <0x01>;
					rotation = <0x10e>;

					port {

						endpoint {
							remote-endpoint = <0x81>;
							data-lanes = <0x01 0x02 0x03 0x04>;
							link-frequencies = <0x00 0x23a4c180>;
							phandle = <0x90>;
						};
					};
				};
			};
		};

		usi@108800c0 {
			compatible = "samsung,exynos850-usi";
			reg = <0x108800c0 0x20>;
			ranges;
			#address-cells = <0x01>;
			#size-cells = <0x01>;
			clock-names = "pclk", "ipclk";
			clocks = <0x5a 0x0d 0x5a 0x0c>;
			samsung,sysreg = <0x1f 0x1010>;
			samsung,mode = <0x03>;
			samsung,clkreq-on;
			status = "okay";

			i2c@10880000 {
				compatible = "samsung,exynos9820-hsi2c";
				reg = <0x10880000 0xc0>;
				clock-names = "hsi2c", "hsi2c_pclk";
				clocks = <0x5a 0x0c 0x5a 0x0d>;
				interrupts = <0x00 0x19c 0x04>;
				pinctrl-names = "default", "camera-on";
				pinctrl-0 = <0x82 0x83>;
				pinctrl-1 = <0x84 0x85>;
				#address-cells = <0x01>;
				#size-cells = <0x00>;
				clock-frequency = <0x186a0>;
				status = "okay";

				sensor@10 {
					compatible = "samsung,s5k3j1";
					reg = <0x10>;
					reset-gpios = <0x86 0x05 0x01>;
					clocks = <0x87>;
					clock-names = "mclk";
					mux-controls = <0x7c>;
					pre-supply = <0x6c>;
					avdd-supply = <0x88>;
					iovdd-supply = <0x6f>;
					dvdd-supply = <0x89>;
					orientation = <0x00>;
					rotation = <0x5a>;
					lens-focus = <0x92>;

					port {

						endpoint {
							remote-endpoint = <0x8a>;
							data-lanes = <0x01 0x02 0x03 0x04>;
							link-frequencies = <0x00 0x35da50e0>;
							phandle = <0x91>;
						};
					};
				};
			};
		};

		usi@108900c0 {
			compatible = "samsung,exynos850-usi";
			reg = <0x108900c0 0x20>;
			ranges;
			#address-cells = <0x01>;
			#size-cells = <0x01>;
			clock-names = "pclk", "ipclk";
			clocks = <0x5a 0x1b 0x5a 0x1a>;
			samsung,sysreg = <0x1f 0x1014>;
			samsung,mode = <0x03>;
			samsung,clkreq-on;
			status = "okay";

			i2c@10890000 {
				compatible = "samsung,exynos9820-hsi2c";
				reg = <0x10890000 0xc0>;
				clock-names = "hsi2c", "hsi2c_pclk";
				clocks = <0x5a 0x1a 0x5a 0x1b>;
				interrupts = <0x00 0x19d 0x04>;
				pinctrl-names = "default", "camera-on";
				pinctrl-0 = <0x8b>;
				pinctrl-1 = <0x8c>;
				#address-cells = <0x01>;
				#size-cells = <0x00>;
				clock-frequency = <0x186a0>;
				status = "okay";

				actuator@c {
					phandle = <0xb6>;
					vddio-supply = <0x8e>;
					vdd-supply = <0xb5>;
					reg = <0x0c>;
					compatible = "asahi-kasei,ak7374";
				};

				actuator@f {
					compatible = "asahi-kasei,ak7374";
					reg = <0x0f>;
					vdd-supply = <0x8d>;
					vddio-supply = <0x8e>;
					phandle = <0x7d>;
				};
			};
		};

		usi@15d300c0 {
			compatible = "samsung,exynos850-usi";
			reg = <0x15d300c0 0x20>;
			ranges;
			#address-cells = <0x01>;
			#size-cells = <0x01>;
			clock-names = "pclk", "ipclk";
			clocks = <0x2f 0x34 0x2f 0x33>;
			samsung,sysreg = <0x2e 0x2010>;
			samsung,mode = <0x03>;
			samsung,clkreq-on;
			status = "okay";

			i2c@15d30000 {
				compatible = "samsung,exynos9820-hsi2c";
				reg = <0x15d30000 0xc0>;
				clock-names = "hsi2c", "hsi2c_pclk";
				clocks = <0x2f 0x33 0x2f 0x34>;
				interrupts = <0x00 0x4f 0x04>;
				pinctrl-names = "default";
				pinctrl-0 = <0x8f>;
				#address-cells = <0x01>;
				#size-cells = <0x00>;
				clock-frequency = <0x186a0>;
				status = "okay";

				pmic@56 {
					compatible = "samsung,s2mpb03-camera-test";
					reg = <0x56>;

					regulators {

						s2mpb03-ldo3 {
							regulator-name = "VDDIO_1.8V_CAM";
							regulator-min-microvolt = <0x1b7740>;
							regulator-max-microvolt = <0x1b7740>;
							phandle = <0x8e>;
						};

						s2mpb03-ldo1 {
							regulator-name = "VDDD_1.0V_CAM";
							regulator-min-microvolt = <0x100590>;
							regulator-max-microvolt = <0x100590>;
							phandle = <0xb1>;
						};

						s2mpb03-ldo2 {
							regulator-name = "VDDQ_1.1V_CAM";
							regulator-min-microvolt = <0x10c8e0>;
							regulator-max-microvolt = <0x10c8e0>;
							phandle = <0xb2>;
						};

						s2mpb03-ldo4 {
							regulator-name = "VDDD_RET_1.0V_CAM";
							regulator-min-microvolt = <0xaae60>;
							regulator-max-microvolt = <0x16b28c>;
							phandle = <0xae>;
						};

						s2mpb03-ldo5 {
							regulator-name = "VDDA_2.4V_CAM";
							regulator-min-microvolt = <0x249f00>;
							regulator-max-microvolt = <0x249f00>;
							phandle = <0xb0>;
						};

						s2mpb03-ldo6 {
							regulator-name = "VDDA_2.8V_CAM";
							regulator-min-microvolt = <0x2ab980>;
							regulator-max-microvolt = <0x2ab980>;
							phandle = <0xaf>;
						};

						s2mpb03-ldo7 {
							regulator-name = "VDD_VM_2.8V_OIS";
							regulator-min-microvolt = <0x2ab980>;
							regulator-max-microvolt = <0x2ab980>;
						};
					};
				};
			};
		};

		camera-csis@17050000 {
			compatible = "samsung,exynos9820-csis";
			reg = <0x17050000 0x1000 0x170e0000 0x100 0x17020500 0x04 0x19162300 0x500 0x170c0000 0x500>;
			reg-names = "csis", "dma-top", "phy-reset", "phy", "dma";
			interrupts = <0x00 0x137 0x04 0x00 0x13d 0x04>;
			interrupt-names = "csis", "dma";
			samsung,pmu-syscon = <0x21>;
			samsung,pmu-phy-offset = <0x730>;
			samsung,phy-reset-bit = <0x01>;
			power-domains = <0x72>;
			clock-names = "csis", "dma", "mmu", "bus";
			clocks = <0x73 0x07 0x73 0x04 0x73 0x05 0x15 0x60>;

			ports {
				#address-cells = <0x01>;
				#size-cells = <0x00>;

				port@0 {
					reg = <0x00>;
					#address-cells = <0x01>;
					#size-cells = <0x00>;

					endpoint@0 {
						reg = <0x00>;
						remote-endpoint = <0x90>;
						data-lanes = <0x01 0x02 0x03 0x04>;
						phandle = <0x81>;
					};

					endpoint@1 {
						reg = <0x01>;
						remote-endpoint = <0x91>;
						data-lanes = <0x01 0x02 0x03 0x04>;
						phandle = <0x8a>;
					};
				};
			};
		};

		usi@108f00c0 {
			compatible = "samsung,exynos850-usi";
			reg = <0x108f00c0 0x20>;
			ranges;
			#address-cells = <0x01>;
			#size-cells = <0x01>;
			clock-names = "pclk", "ipclk";
			clocks = <0x5a 0x1d 0x5a 0x1c>;
			samsung,sysreg = <0x1f 0x102c>;
			samsung,mode = <0x03>;
			samsung,clkreq-on;
			status = "okay";

			i2c@108f0000 {
				compatible = "samsung,exynos9820-hsi2c";
				reg = <0x108f0000 0xc0>;
				clock-names = "hsi2c", "hsi2c_pclk";
				clocks = <0x5a 0x1c 0x5a 0x1d>;
				interrupts = <0x00 0x1a3 0x04>;
				pinctrl-names = "default", "camera-on";
				pinctrl-0 = <0x93>;
				pinctrl-1 = <0x94>;
				#address-cells = <0x01>;
				#size-cells = <0x00>;
				clock-frequency = <0x186a0>;
				status = "okay";

				actuator@c {
					compatible = "asahi-kasei,ak7374";
					reg = <0x0c>;
					vdd-supply = <0x95>;
					vddio-supply = <0x6f>;
					phandle = <0x92>;
				};
			};
		};

		serial@10840000 {
			samsung,usi-serial-v2;
			compatible = "samsung,exynos7870-uart", "samsung,exynos8895-uart";
			reg = <0x10840000 0x100>;
			interrupts = <0x00 0x198 0x04>;
			clock-names = "uart", "clk_uart_baud0";
			clocks = <0x5a 0x21 0x5a 0x20>;
			samsung,uart-fifosize = <0x100>;
			pinctrl-names = "default";
			pinctrl-0 = <0x96>;
			status = "okay";

			bluetooth {
				compatible = "brcm,bcm4349-bt";
				shutdown-gpios = <0x97 0x00 0x00>;
				device-wakeup-gpios = <0x86 0x00 0x00>;
				interrupt-parent = <0x4d>;
				interrupts = <0x03 0x01>;
				interrupt-names = "host-wakeup";
				pinctrl-names = "default";
				pinctrl-0 = <0x98 0x99 0x9a>;
				max-speed = <0x2dc6c0>;
			};
		};

		usi@108e00c0 {
			compatible = "samsung,exynos850-usi";
			reg = <0x108e00c0 0x20>;
			ranges;
			#address-cells = <0x01>;
			#size-cells = <0x01>;
			clock-names = "pclk", "ipclk";
			clocks = <0x5a 0x25 0x5a 0x24>;
			samsung,sysreg = <0x1f 0x1028>;
			samsung,mode = <0x03>;
			samsung,clkreq-on;
			status = "okay";

			i2c@108e0000 {
				compatible = "samsung,exynos9820-hsi2c";
				reg = <0x108e0000 0xc0>;
				clock-names = "hsi2c", "hsi2c_pclk";
				clocks = <0x5a 0x24 0x5a 0x25>;
				interrupts = <0x00 0x1a2 0x04>;
				pinctrl-names = "default";
				pinctrl-0 = <0x9b>;
				#address-cells = <0x01>;
				#size-cells = <0x00>;
				clock-frequency = <0x61a80>;
				status = "okay";

				nfc@27 {
					compatible = "samsung,s3fwrn5-i2c";
					reg = <0x27>;
					interrupt-parent = <0x1d>;
					interrupts = <0x02 0x01>;
					en-gpios = <0x9c 0x02 0x00>;
					clocks = <0x21 0x00>;
					wake-gpios = <0x9c 0x03 0x00>;
					pinctrl-names = "default";
					pinctrl-0 = <0x9d 0x9e 0x9f>;
				};
			};
		};

		usi@109700c0 {
			compatible = "samsung,exynos850-usi";
			reg = <0x109700c0 0x20>;
			ranges;
			#address-cells = <0x01>;
			#size-cells = <0x01>;
			clock-names = "pclk", "ipclk";
			clocks = <0x5a 0x29 0x5a 0x28>;
			samsung,sysreg = <0x1f 0x1048>;
			samsung,mode = <0x02>;
			status = "okay";

			spi@10970000 {
				compatible = "samsung,exynos850-spi";
				reg = <0x10970000 0x30>;
				interrupts = <0x00 0x1aa 0x04>;
				clock-names = "spi", "spi_busclk0";
				clocks = <0x5a 0x29 0x5a 0x28>;
				samsung,spi-fifosize = <0x40>;
				pinctrl-names = "default";
				pinctrl-0 = <0xa0 0xa1>;
				cs-gpios = <0xa2 0x03 0x01>;
				#address-cells = <0x01>;
				#size-cells = <0x00>;
				num-cs = <0x01>;
				status = "okay";

				shub@0 {
					compatible = "rohm,dh2228fv";
					reg = <0x00>;
					spi-max-frequency = <0x17d7840>;
					spi-cpol;
					spi-cpha;
					pinctrl-names = "default";
					pinctrl-0 = <0xa3 0xa4 0xa5 0xa6 0xa7 0xa8>;
				};
			};
		};

		usi@108600c0 {
			compatible = "samsung,exynos850-usi";
			reg = <0x108600c0 0x20>;
			ranges;
			#address-cells = <0x01>;
			#size-cells = <0x01>;
			clock-names = "pclk", "ipclk";
			clocks = <0x5a 0x15 0x5a 0x14>;
			samsung,sysreg = <0x1f 0x1008>;
			samsung,mode = <0x03>;
			status = "okay";

			i2c@10860000 {
				compatible = "samsung,exynos9820-hsi2c";
				reg = <0x10860000 0xc0>;
				clock-names = "hsi2c", "hsi2c_pclk";
				clocks = <0x5a 0x14 0x5a 0x15>;
				interrupts = <0x00 0x19a 0x04>;
				pinctrl-names = "default", "camera-on";
				pinctrl-0 = <0xac>;
				pinctrl-1 = <0xad>;
				#address-cells = <0x01>;
				#size-cells = <0x00>;
				clock-frequency = <0xf4240>;
				samsung,fast-plus-mode;
				samsung,reset-before-trans;
				status = "okay";

				sensor@10 {
					lens-focus = <0xb6>;
					compatible = "samsung,s5k2l4";
					reg = <0x10>;
					reset-gpios = <0x86 0x06 0x01>;
					clocks = <0x7b>;
					clock-names = "mclk";
					retention-supply = <0xae>;
					avdd28-supply = <0xaf>;
					avdd24-supply = <0xb0>;
					core-supply = <0xb1>;
					iovdd-supply = <0x8e>;
					vddq-supply = <0xb2>;
					orientation = <0x01>;
					rotation = <0x10e>;

					port {

						endpoint {
							remote-endpoint = <0xb3>;
							data-lanes = <0x01 0x02 0x03 0x04>;
							link-frequencies = <0x00 0x3703dcc0 0x00 0x284af100>;
							phandle = <0xb4>;
						};
					};
				};
			};
		};

		camera-csis@17030000 {
			compatible = "samsung,exynos9820-csis";
			reg = <0x17030000 0x1000 0x170e0000 0x100 0x17020500 0x04 0x19160b00 0x500 0x170a0000 0x500>;
			reg-names = "csis", "dma-top", "phy-reset", "phy", "dma";
			interrupts = <0x00 0x135 0x04 0x00 0x13b 0x04>;
			interrupt-names = "csis", "dma";
			samsung,pmu-syscon = <0x21>;
			samsung,pmu-phy-offset = <0x70c>;
			samsung,phy-reset-bit = <0x00>;
			samsung,phy-dc-combo;
			power-domains = <0x72>;
			clock-names = "csis", "dma", "mmu", "bus";
			clocks = <0x73 0x06 0x73 0x04 0x73 0x05 0x15 0x60>;

			ports {
				#address-cells = <0x01>;
				#size-cells = <0x00>;

				port@0 {
					reg = <0x00>;

					endpoint {
						remote-endpoint = <0xb4>;
						data-lanes = <0x01 0x02 0x03 0x04>;
						phandle = <0xb3>;
					};
				};
			};
		};
	};

	sram@2039000 {
		compatible = "mmio-sram";
		reg = <0x00 0x2039000 0x30000>;
		#address-cells = <0x01>;
		#size-cells = <0x01>;
		ranges = <0x00 0x00 0x2039000 0x30000>;
		phandle = <0x12>;
	};

	timer {
		compatible = "arm,armv8-timer";
		interrupts = <0x01 0x0d 0xff08 0x01 0x0e 0xff08 0x01 0x0b 0xff08 0x01 0x0a 0xff08>;
		clock-frequency = <0x18cba80>;
	};

	thermal-zones {

		cpucl0-thermal {
			polling-delay-passive = <0x32>;
			polling-delay = <0x3e8>;
			thermal-sensors = <0x43 0x02>;

			trips {

				little-switch-on {
					temperature = <0x124f8>;
					hysteresis = <0x7d0>;
					type = "passive";
				};

				little-mitigate {
					temperature = <0x13880>;
					hysteresis = <0x1388>;
					type = "passive";
					phandle = <0x44>;
				};

				little-hot {
					temperature = <0x19a28>;
					hysteresis = <0x1388>;
					type = "hot";
				};

				little-critical {
					temperature = <0x1adb0>;
					hysteresis = <0x7d0>;
					type = "critical";
				};
			};

			cooling-maps {

				map0 {
					trip = <0x44>;
					cooling-device = <0x02 0x02 0xffffffff 0x03 0x02 0xffffffff 0x04 0x02 0xffffffff 0x05 0x02 0xffffffff>;
				};
			};
		};

		cpucl1-thermal {
			polling-delay-passive = <0x32>;
			polling-delay = <0x3e8>;
			thermal-sensors = <0x43 0x01>;

			trips {

				mid-switch-on {
					temperature = <0x124f8>;
					hysteresis = <0x7d0>;
					type = "passive";
				};

				mid-mitigate {
					temperature = <0x14438>;
					hysteresis = <0x1388>;
					type = "passive";
					phandle = <0x45>;
				};

				mid-hot {
					temperature = <0x19a28>;
					hysteresis = <0x1388>;
					type = "hot";
				};

				mid-critical {
					temperature = <0x1adb0>;
					hysteresis = <0x7d0>;
					type = "critical";
				};
			};

			cooling-maps {

				map0 {
					trip = <0x45>;
					cooling-device = <0x06 0x02 0xffffffff 0x07 0x02 0xffffffff>;
				};
			};
		};

		cpucl2-thermal {
			polling-delay-passive = <0x19>;
			polling-delay = <0x3e8>;
			thermal-sensors = <0x43 0x00>;

			trips {

				big-switch-on {
					temperature = <0x124f8>;
					hysteresis = <0x7d0>;
					type = "passive";
				};

				big-mitigate {
					temperature = <0x14438>;
					hysteresis = <0x1388>;
					type = "passive";
					phandle = <0x46>;
				};

				big-hotplug {
					temperature = <0x17700>;
					hysteresis = <0x1388>;
					type = "passive";
					phandle = <0x47>;
				};

				big-hot {
					temperature = <0x19a28>;
					hysteresis = <0x1388>;
					type = "hot";
				};

				big-critical {
					temperature = <0x1adb0>;
					hysteresis = <0x7d0>;
					type = "critical";
				};
			};

			cooling-maps {

				map0 {
					trip = <0x46>;
					cooling-device = <0x08 0xffffffff 0xffffffff 0x09 0xffffffff 0xffffffff>;
				};

				map1 {
					trip = <0x47>;
					cooling-device = <0x08 0x12 0x12 0x09 0x12 0x12>;
				};
			};
		};

		g3d-thermal {
			polling-delay-passive = <0xfa>;
			polling-delay = <0x3e8>;
			thermal-sensors = <0x43 0x03>;

			trips {

				g3d-hot {
					temperature = <0x186a0>;
					hysteresis = <0x1388>;
					type = "hot";
				};

				g3d-critical {
					temperature = <0x1adb0>;
					hysteresis = <0x7d0>;
					type = "critical";
				};

				s10-gpu-passive {
					temperature = <0xfde8>;
					hysteresis = <0x1388>;
					type = "passive";
					phandle = <0x64>;
				};
			};

			cooling-maps {

				s10-gpu-limit {
					trip = <0x64>;
					cooling-device = <0x65 0x05 0x05>;
				};
			};
		};

		isp-thermal {
			polling-delay-passive = <0xfa>;
			polling-delay = <0x1388>;
			thermal-sensors = <0x43 0x04>;

			trips {

				isp-hot {
					temperature = <0x186a0>;
					hysteresis = <0x1388>;
					type = "hot";
				};

				isp-critical {
					temperature = <0x1adb0>;
					hysteresis = <0x7d0>;
					type = "critical";
				};
			};
		};
	};

	battery {
		compatible = "simple-battery";
		over-voltage-threshold-microvolt = <0x44aa20>;
		voltage-min-design-microvolt = <0x3519c0>;
		voltage-max-design-microvolt = <0x426030>;
		constant-charge-current-max-microamp = <0x16e360>;
		charge-full-design-microamp-hours = <0x325aa0>;
		phandle = <0x36>;
	};

	chosen {
		samsung,postmarketos-cpuidle-test = "ananke-c2-production-v1";
		u-boot,version = "2026.01-gdec4927b4ad5";
		#address-cells = <0x02>;
		#size-cells = <0x01>;
		ranges;
		stdout-path = "/soc@0/serial@10440000";

		framebuffer@ca000000 {
			compatible = "simple-framebuffer";
			reg = <0x00 0xca000000 0x10b3000>;
			width = <0x5a0>;
			height = <0xbe0>;
			stride = <0x1680>;
			format = "a8r8g8b8";
			panel = <0x48>;

			dummy-panel {
				width-mm = <0x42>;
				height-mm = <0x8c>;
				phandle = <0x48>;
			};
		};
	};

	gpio-keys {
		compatible = "gpio-keys";
		pinctrl-0 = <0x49 0x4a 0x4b 0x4c>;
		pinctrl-names = "default";

		key-volup {
			label = "Volume Up Key";
			linux,code = <0x73>;
			gpios = <0x13 0x03 0x01>;
		};

		key-voldown {
			label = "Volume Down Key";
			linux,code = <0x72>;
			gpios = <0x13 0x04 0x01>;
		};

		key-wink {
			label = "Wink Key";
			linux,code = <0x98>;
			gpios = <0x13 0x06 0x01>;
		};

		key-power {
			label = "Power Key";
			linux,code = <0x74>;
			gpios = <0x4d 0x04 0x01>;
			wakeup-source;
		};
	};

	reserved-memory {
		#address-cells = <0x02>;
		#size-cells = <0x01>;
		ranges;

		sec_debug_magic@80000000 {
			reg = <0x00 0x80000000 0x1000>;
			no-map;
		};

		kaslr_seed@80001000 {
			reg = <0x00 0x80001000 0x1000>;
			no-map;
		};

		el2_code@87000000 {
			reg = <0x00 0x87000000 0x200000>;
			no-map;
		};

		mm_debug@91200000 {
			reg = <0x00 0x91200000 0x1000>;
			no-map;
		};

		secure_camera@96000000 {
			reg = <0x00 0x96000000 0x2200000>;
			no-map;
		};

		seclog_mem@c0000000 {
			reg = <0x00 0xc0000000 0x80000>;
			no-map;
		};

		framebuffer_region@ca000000 {
			iommu-addresses = <0xab 0xca000000 0x10b3000>;
			phandle = <0xa9>;
			reg = <0x00 0xca000000 0x10b3000>;
			no-map;
		};

		modem_spare@d0000000 {
			reg = <0x00 0xd0000000 0x1600000>;
			no-map;
		};

		modem_if@f0000000 {
			reg = <0x00 0xf0000000 0xb900000>;
			no-map;
		};

		cp_ram_logging@fb900000 {
			reg = <0x00 0xfb900000 0x2000000>;
			no-map;
		};

		el2_earlymem@9fd800000 {
			reg = <0x09 0xfd800000 0x2800000>;
			no-map;
		};
	};

	regulator-0 {
		compatible = "regulator-fixed";
		regulator-name = "dummy_reg";
		phandle = <0x22>;
	};

	gpio-regulator {
		compatible = "regulator-fixed";
		regulator-name = "haptic";
		regulator-min-microvolt = <0x1b7740>;
		regulator-max-microvolt = <0x1b7740>;
		gpio = <0x4e 0x07 0x00>;
		enable-active-high;
		regulator-boot-on;
		phandle = <0x34>;
	};

	s10-gpu-opp-table {
		compatible = "operating-points-v2";
		phandle = <0x63>;

		opp-156000000 {
			opp-hz = <0x00 0x94c5f00>;
		};

		opp-200000000 {
			opp-hz = <0x00 0xbebc200>;
		};

		opp-260000000 {
			opp-hz = <0x00 0xf7f4900>;
		};

		opp-325000000 {
			opp-hz = <0x00 0x135f1b40>;
		};

		opp-377000000 {
			opp-hz = <0x00 0x16789040>;
		};

		opp-433000000 {
			opp-hz = <0x00 0x19cf0e40>;
		};
	};
};
